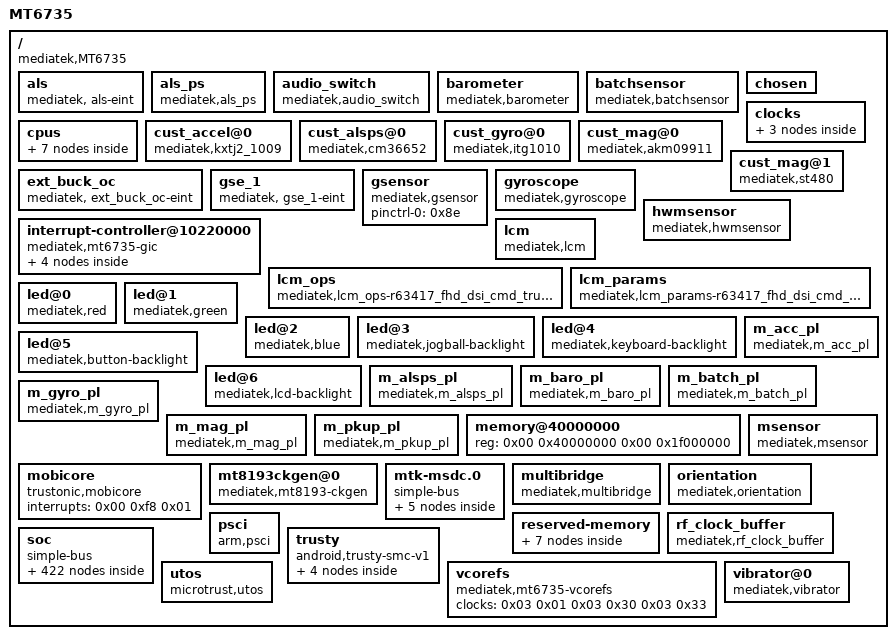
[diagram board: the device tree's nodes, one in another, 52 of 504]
/dts-v1/;

/ {
	#address-cells = <0x02>;
	#size-cells = <0x02>;
	compatible = "mediatek,MT6735";
	interrupt-parent = <0x01>;
	model = "MT6735";

	als {
		compatible = "mediatek, als-eint";
		debounce = <0x03 0x00>;
		interrupt-parent = <0x0c>;
		interrupts = <0x03 0x02>;
		status = "okay";
	};

	als_ps {
		compatible = "mediatek,als_ps";
		pinctrl-0 = <0x8f>;
		pinctrl-1 = <0x90>;
		pinctrl-names = "pin_default\0pin_cfg";
		status = "okay";
	};

	audio_switch {
		compatible = "mediatek,audio_switch";
	};

	barometer {
		compatible = "mediatek,barometer";
	};

	batchsensor {
		compatible = "mediatek,batchsensor";
	};

	chosen {
		bootargs = "console=tty0 console=ttyMT0,921600n1 root=/dev/ram initrd=0x44000000,0x300000 loglevel=8 androidboot.hardware=mt6735";
	};

	clocks {

		clk26m {
			#clock-cells = <0x00>;
			clock-frequency = <0x18cba80>;
			compatible = "fixed-clock";
			linux,phandle = <0x3d>;
			phandle = <0x3d>;
		};

		clk32k {
			#clock-cells = <0x00>;
			clock-frequency = <0x7d00>;
			compatible = "fixed-clock";
		};

		clk_null {
			#clock-cells = <0x00>;
			clock-frequency = <0x00>;
			compatible = "fixed-clock";
		};
	};

	cpus {
		#address-cells = <0x01>;
		#size-cells = <0x00>;

		cpu@000 {
			clock-frequency = "M|m";
			compatible = "arm,cortex-a53";
			cpu-idle-states = <0x0d 0x0d 0x0e 0x0e>;
			cpu-release-addr = <0x00 0x40000200>;
			device_type = "cpu";
			enable-method = "mt-boot";
			linux,phandle = <0x0f>;
			phandle = <0x0f>;
			reg = <0x00>;
		};

		cpu@001 {
			clock-frequency = "M|m";
			compatible = "arm,cortex-a53";
			cpu-idle-states = <0x0d 0x0d 0x0e 0x0e>;
			cpu-release-addr = <0x00 0x40000200>;
			device_type = "cpu";
			enable-method = "mt-boot";
			linux,phandle = <0x10>;
			phandle = <0x10>;
			reg = <0x01>;
		};

		cpu@002 {
			clock-frequency = "M|m";
			compatible = "arm,cortex-a53";
			cpu-idle-states = <0x0d 0x0d 0x0e 0x0e>;
			cpu-release-addr = <0x00 0x40000200>;
			device_type = "cpu";
			enable-method = "mt-boot";
			linux,phandle = <0x11>;
			phandle = <0x11>;
			reg = <0x02>;
		};

		cpu@003 {
			clock-frequency = "M|m";
			compatible = "arm,cortex-a53";
			cpu-idle-states = <0x0d 0x0d 0x0e 0x0e>;
			cpu-release-addr = <0x00 0x40000200>;
			device_type = "cpu";
			enable-method = "mt-boot";
			linux,phandle = <0x12>;
			phandle = <0x12>;
			reg = <0x03>;
		};

		idle-states {
			entry-method = "arm,psci";

			cluster-sleep-0 {
				arm,psci-suspend-param = <0x1010000>;
				compatible = "arm,idle-state";
				entry-latency-us = <0x320>;
				exit-latency-us = <0x3e8>;
				linux,phandle = <0x0d>;
				min-residency-us = <0x7d0>;
				phandle = <0x0d>;
			};

			cpu-sleep-0-0 {
				arm,psci-suspend-param = <0x10000>;
				compatible = "arm,idle-state";
				entry-latency-us = <0x258>;
				exit-latency-us = <0x258>;
				linux,phandle = <0x0e>;
				min-residency-us = <0x4b0>;
				phandle = <0x0e>;
			};
		};
	};

	cust_accel@0 {
		compatible = "mediatek,kxtj2_1009";
		direction = <0x04>;
		firlen = <0x00>;
		i2c_addr = <0x4c 0x00 0x00 0x00>;
		i2c_num = <0x02>;
		is_batch_supported = <0x00>;
		power_id = <0xffff>;
		power_vol = <0x00>;
	};

	cust_alsps@0 {
		als_level = <0x00 0x148 0x35d 0x561 0xc35 0x1e29 0x1e57 0x314d 0x5a16 0x6f0e 0x81fa 0xb80c 0xe15e 0xe15e 0xffff>;
		als_value = <0x00 0x85 0x130 0x1f6 0x3ec 0x7d5 0xbf2 0x138d 0x1f48 0x271a 0x2ee0 0x3e80 0x4e20 0x4e20 0x4e20 0x4e20>;
		compatible = "mediatek,cm36652";
		i2c_addr = <0x60 0x00 0x00 0x00>;
		i2c_num = <0x02>;
		is_batch_supported_als = <0x00>;
		is_batch_supported_ps = <0x00>;
		polling_mode_als = <0x01>;
		polling_mode_ps = <0x00>;
		power_id = <0xffff>;
		power_vol = <0x00>;
		ps_threshold_high = <0x1a>;
		ps_threshold_low = <0x15>;
	};

	cust_gyro@0 {
		compatible = "mediatek,itg1010";
		direction = <0x03>;
		firlen = <0x00>;
		i2c_addr = <0x68 0x00 0x00 0x00>;
		i2c_num = <0x02>;
		is_batch_supported = <0x00>;
		power_id = <0xffff>;
		power_vol = <0x00>;
	};

	cust_mag@0 {
		compatible = "mediatek,akm09911";
		direction = <0x03>;
		i2c_addr = <0x0c 0x00 0x00 0x00>;
		i2c_num = <0x02>;
		is_batch_supported = <0x00>;
		power_id = <0xffff>;
		power_vol = <0x00>;
	};

	cust_mag@1 {
		compatible = "mediatek,st480";
		direction = <0x05>;
		i2c_addr = <0x0c 0x00 0x00 0x00>;
		i2c_num = <0x02>;
		is_batch_supported = <0x00>;
		power_id = <0xffff>;
		power_vol = <0x00>;
	};

	ext_buck_oc {
		compatible = "mediatek, ext_buck_oc-eint";
		debounce = <0x4e 0x00>;
		interrupt-parent = <0x0c>;
		interrupts = <0x4e 0x04>;
		status = "okay";
	};

	gse_1 {
		compatible = "mediatek, gse_1-eint";
		debounce = <0x04 0x00>;
		interrupt-parent = <0x0c>;
		interrupts = <0x04 0x01>;
		status = "okay";
	};

	gsensor {
		compatible = "mediatek,gsensor";
		pinctrl-0 = <0x8e>;
		pinctrl-names = "pin_cfg";
		status = "okay";
	};

	gyroscope {
		compatible = "mediatek,gyroscope";
		debounce = <0x43 0x00>;
		interrupt-parent = <0x0c>;
		interrupts = <0x43 0x08>;
		pinctrl-0 = <0x91>;
		pinctrl-1 = <0x92>;
		pinctrl-names = "pin_default\0pin_cfg";
		status = "okay";
	};

	hwmsensor {
		compatible = "mediatek,hwmsensor";
	};

	interrupt-controller@10220000 {
		#address-cells = <0x00>;
		#interrupt-cells = <0x03>;
		compatible = "mediatek,mt6735-gic";
		interrupt-controller;
		linux,phandle = <0x01>;
		mediatek,wdt_irq = <0xa0>;
		phandle = <0x01>;
		reg = <0x00 0x10221000 0x00 0x1000 0x00 0x10222000 0x00 0x1000 0x00 0x10200620 0x00 0x1000>;

		gic-cpuif@0 {
			compatible = "arm,gic-cpuif";
			cpu = <0x0f>;
			cpuif-id = <0x00>;
		};

		gic-cpuif@1 {
			compatible = "arm,gic-cpuif";
			cpu = <0x10>;
			cpuif-id = <0x01>;
		};

		gic-cpuif@2 {
			compatible = "arm,gic-cpuif";
			cpu = <0x11>;
			cpuif-id = <0x02>;
		};

		gic-cpuif@3 {
			compatible = "arm,gic-cpuif";
			cpu = <0x12>;
			cpuif-id = <0x03>;
		};
	};

	lcm {
		compatible = "mediatek,lcm";
	};

	lcm_ops {
		backlight = <0x04 0x05 0x03 0x51 0x01 0xff>;
		compare_id = <0x03 0x01 0x01 0x01 0x03 0x02 0x01 0x01 0x03 0x01 0x01 0x00 0x03 0x02 0x01 0x0a 0x03 0x01 0x01 0x01 0x03 0x02 0x01 0x0a 0x04 0x04 0x05 0x01 0x00 0x37 0x02 0x00 0x04 0x07 0x03 0xf4 0x01 0x95>;
		compatible = "mediatek,lcm_ops-r63417_fhd_dsi_cmd_truly_nt50358_drv";
		init = <0x01 0x01 0x01 0x00 0x01 0x02 0x01 0x01 0x01 0x03 0x01 0x01 0x03 0x02 0x01 0x0a 0x02 0x01 0x02 0x00 0x0a 0x02 0x01 0x02 0x01 0x0a 0x03 0x01 0x01 0x01 0x03 0x02 0x01 0x01 0x03 0x01 0x01 0x00 0x03 0x02 0x01 0x0a 0x03 0x01 0x01 0x01 0x03 0x02 0x01 0x0a 0x04 0x05 0x03 0xb0 0x01 0x00 0x04 0x05 0x03 0xd6 0x01 0x01 0x04 0x05 0x03 0x51 0x01 0xff 0x04 0x05 0x03 0x53 0x01 0x0c 0x04 0x05 0x2a 0xc6 0x28 0x77 0x01 0x71 0x07 0x65 0x00 0x00 0x00 0x00 0x00 0x00 0x00 0x00 0x00 0x00 0x00 0x00 0x09 0x19 0x09 0x77 0x01 0x71 0x07 0x65 0x00 0x00 0x00 0x00 0x00 0x00 0x00 0x00 0x00 0x00 0x00 0x00 0x09 0x19 0x09 0x04 0x05 0x20 0xc7 0x1e 0x01 0x0c 0x14 0x1e 0x2d 0x3c 0x48 0x58 0x3d 0x44 0x4f 0x5c 0x65 0x6d 0x75 0x01 0x0c 0x14 0x1d 0x2c 0x39 0x44 0x54 0x39 0x41 0x4d 0x5a 0x63 0x6b 0x74 0x04 0x05 0x15 0xc8 0x13 0x01 0x00 0xff 0xff 0x00 0xfc 0x00 0x00 0xff 0xff 0x00 0xfc 0x00 0x00 0xff 0xff 0x00 0xfc 0x00 0x04 0x05 0x03 0x35 0x01 0x00 0x04 0x05 0x04 0xb6 0x02 0x3a 0xd3 0x04 0x05 0x02 0x29 0x00 0x04 0x05 0x02 0x11 0x00 0x03 0x02 0x01 0x78>;
		suspend = <0x04 0x05 0x02 0x28 0x00 0x03 0x02 0x01 0x14 0x04 0x05 0x02 0x10 0x00 0x04 0x05 0x03 0xb0 0x01 0x00 0x04 0x05 0x03 0xb1 0x01 0x01 0x03 0x02 0x01 0x50 0x03 0x02 0x01 0x0a 0x01 0x01 0x01 0x00 0x01 0x02 0x01 0x01 0x01 0x03 0x01 0x00>;
	};

	lcm_params {
		compatible = "mediatek,lcm_params-r63417_fhd_dsi_cmd_truly_nt50358_drv";
		lcm_params-dbi-clock_freq;
		lcm_params-dbi-cpu_write_bits;
		lcm_params-dbi-ctrl_io_driving_current;
		lcm_params-dbi-data_format;
		lcm_params-dbi-data_width;
		lcm_params-dbi-io_driving_current;
		lcm_params-dbi-msb_io_driving_current;
		lcm_params-dbi-parallel-params0;
		lcm_params-dbi-parallel-params1;
		lcm_params-dbi-port;
		lcm_params-dbi-serial-params0;
		lcm_params-dbi-serial-params1;
		lcm_params-dbi-serial-params2;
		lcm_params-dbi-te_edge_polarity;
		lcm_params-dbi-te_hs_delay_cnt;
		lcm_params-dbi-te_mode;
		lcm_params-dbi-te_vs_width_cnt;
		lcm_params-dbi-te_vs_width_cnt_div;
		lcm_params-dpi-PLL_CLOCK;
		lcm_params-dpi-bg_height;
		lcm_params-dpi-bg_width;
		lcm_params-dpi-bit_swap;
		lcm_params-dpi-clk_pol;
		lcm_params-dpi-de_pol;
		lcm_params-dpi-dpi_clk_div;
		lcm_params-dpi-dpi_clk_duty;
		lcm_params-dpi-dpi_clock;
		lcm_params-dpi-embsync;
		lcm_params-dpi-format;
		lcm_params-dpi-height;
		lcm_params-dpi-hsync_back_porch;
		lcm_params-dpi-hsync_front_porch;
		lcm_params-dpi-hsync_pol;
		lcm_params-dpi-hsync_pulse_width;
		lcm_params-dpi-i2x_edge;
		lcm_params-dpi-i2x_en;
		lcm_params-dpi-intermediat_buffer_num;
		lcm_params-dpi-io_driving_current;
		lcm_params-dpi-is_serial_output;
		lcm_params-dpi-lsb_io_driving_current;
		lcm_params-dpi-lvds_tx_en;
		lcm_params-dpi-mipi_pll_clk_div1;
		lcm_params-dpi-mipi_pll_clk_div2;
		lcm_params-dpi-mipi_pll_clk_fbk_div;
		lcm_params-dpi-mipi_pll_clk_ref;
		lcm_params-dpi-rgb_order;
		lcm_params-dpi-ssc_disable;
		lcm_params-dpi-ssc_range;
		lcm_params-dpi-vsync_back_porch;
		lcm_params-dpi-vsync_front_porch;
		lcm_params-dpi-vsync_pol;
		lcm_params-dpi-vsync_pulse_width;
		lcm_params-dpi-width;
		lcm_params-dsi-CLK_HS_EXIT;
		lcm_params-dsi-CLK_HS_POST;
		lcm_params-dsi-CLK_HS_PRPR;
		lcm_params-dsi-CLK_TRAIL;
		lcm_params-dsi-CLK_ZERO;
		lcm_params-dsi-CONT_DET;
		lcm_params-dsi-DA_HS_EXIT;
		lcm_params-dsi-DSI_RMEM_CONTI;
		lcm_params-dsi-DSI_WMEM_CONTI;
		lcm_params-dsi-HS_PRPR;
		lcm_params-dsi-HS_TRAIL;
		lcm_params-dsi-LPX;
		lcm_params-dsi-LPX_WAIT;
		lcm_params-dsi-TA_GET;
		lcm_params-dsi-TA_GO;
		lcm_params-dsi-TA_SACK;
		lcm_params-dsi-TA_SURE;
		lcm_params-dsi-VC_NUM;
		lcm_params-dsi-ZERO;
		lcm_params-dsi-clk_lp_per_line_enable = <0x00>;
		lcm_params-dsi-compatibility_for_nvk;
		lcm_params-dsi-cont_clock;
		lcm_params-dsi-customization_esd_check_enable = <0x00>;
		lcm_params-dsi-data_format = <0x02 0x00 0x00 0x02>;
		lcm_params-dsi-dsi_clock;
		lcm_params-dsi-dual_dsi_type;
		lcm_params-dsi-edp_panel;
		lcm_params-dsi-esd_check_enable = <0x01>;
		lcm_params-dsi-fbk_div;
		lcm_params-dsi-fbk_sel;
		lcm_params-dsi-horizontal_active_pixel = <0x438>;
		lcm_params-dsi-horizontal_backporch = <0x3c>;
		lcm_params-dsi-horizontal_backporch_word_count;
		lcm_params-dsi-horizontal_backportch_byte;
		lcm_params-dsi-horizontal_blanking_pixel;
		lcm_params-dsi-horizontal_bllp;
		lcm_params-dsi-horizontal_frontporch = <0x64>;
		lcm_params-dsi-horizontal_frontporch_byte;
		lcm_params-dsi-horizontal_frontporch_word_count;
		lcm_params-dsi-horizontal_sync_active = <0x0a>;
		lcm_params-dsi-horizontal_sync_active_byte;
		lcm_params-dsi-horizontal_sync_active_word_count;
		lcm_params-dsi-intermediat_buffer_num;
		lcm_params-dsi-lane_num = <0x04>;
		lcm_params-dsi-lane_swap0;
		lcm_params-dsi-lane_swap1;
		lcm_params-dsi-lane_swap_en;
		lcm_params-dsi-lcm_esd_check_table0 = <0x0a 0x01 0x1c 0x00>;
		lcm_params-dsi-lcm_esd_check_table1;
		lcm_params-dsi-lcm_esd_check_table2;
		lcm_params-dsi-lcm_ext_te_enable;
		lcm_params-dsi-lcm_ext_te_monitor;
		lcm_params-dsi-lcm_int_te_monitor;
		lcm_params-dsi-lcm_int_te_period;
		lcm_params-dsi-line_byte;
		lcm_params-dsi-mode = <0x00>;
		lcm_params-dsi-noncont_clock;
		lcm_params-dsi-noncont_clock_period;
		lcm_params-dsi-packet_size = <0x100>;
		lcm_params-dsi-pll_clock = <0x1c2>;
		lcm_params-dsi-pll_div1;
		lcm_params-dsi-pll_div2;
		lcm_params-dsi-pll_select;
		lcm_params-dsi-ps = <0x02>;
		lcm_params-dsi-rg_bic;
		lcm_params-dsi-rg_bir;
		lcm_params-dsi-rg_bp;
		lcm_params-dsi-rgb_byte;
		lcm_params-dsi-ssc_disable;
		lcm_params-dsi-ssc_range;
		lcm_params-dsi-switch_mode = <0x02>;
		lcm_params-dsi-switch_mode_enable = <0x00>;
		lcm_params-dsi-ufoe_enable;
		lcm_params-dsi-ufoe_params;
		lcm_params-dsi-vertical_active_line = <0x780>;
		lcm_params-dsi-vertical_backporch = <0x08>;
		lcm_params-dsi-vertical_frontporch = <0x0a>;
		lcm_params-dsi-vertical_frontporch_for_low_power;
		lcm_params-dsi-vertical_sync_active = <0x02>;
		lcm_params-dsi-vertical_vfp_lp;
		lcm_params-dsi-word_count;
		lcm_params-io_select_mode;
		lcm_params-od_table;
		lcm_params-od_table_size;
		lcm_params-physical_height;
		lcm_params-physical_width;
		lcm_params-resolution = <0x438 0x780>;
		lcm_params-types = <0x02 0x00 0x00 0x00>;
	};

	led@0 {
		compatible = "mediatek,red";
		data = <0x01>;
		led_mode = <0x00>;
		pwm_config = <0x00 0x00 0x00 0x00 0x00>;
	};

	led@1 {
		compatible = "mediatek,green";
		data = <0x01>;
		led_mode = <0x00>;
		pwm_config = <0x00 0x00 0x00 0x00 0x00>;
	};

	led@2 {
		compatible = "mediatek,blue";
		data = <0x01>;
		led_mode = <0x00>;
		pwm_config = <0x00 0x00 0x00 0x00 0x00>;
	};

	led@3 {
		compatible = "mediatek,jogball-backlight";
		data = <0x01>;
		led_mode = <0x00>;
		pwm_config = <0x00 0x00 0x00 0x00 0x00>;
	};

	led@4 {
		compatible = "mediatek,keyboard-backlight";
		data = <0x01>;
		led_mode = <0x00>;
		pwm_config = <0x00 0x00 0x00 0x00 0x00>;
	};

	led@5 {
		compatible = "mediatek,button-backlight";
		data = <0x01>;
		led_mode = <0x00>;
		pwm_config = <0x00 0x00 0x00 0x00 0x00>;
	};

	led@6 {
		compatible = "mediatek,lcd-backlight";
		data = <0x01>;
		led_mode = <0x05>;
		pwm_config = <0x00 0x00 0x00 0x00 0x00>;
	};

	m_acc_pl {
		compatible = "mediatek,m_acc_pl";
	};

	m_alsps_pl {
		compatible = "mediatek,m_alsps_pl";
	};

	m_baro_pl {
		compatible = "mediatek,m_baro_pl";
	};

	m_batch_pl {
		compatible = "mediatek,m_batch_pl";
	};

	m_gyro_pl {
		compatible = "mediatek,m_gyro_pl";
	};

	m_mag_pl {
		compatible = "mediatek,m_mag_pl";
	};

	m_pkup_pl {
		compatible = "mediatek,m_pkup_pl";
	};

	memory@40000000 {
		device_type = "memory";
		reg = <0x00 0x40000000 0x00 0x1f000000>;
	};

	mobicore {
		compatible = "trustonic,mobicore";
		interrupts = <0x00 0xf8 0x01>;
	};

	msensor {
		compatible = "mediatek,msensor";
	};

	mt8193ckgen@0 {
		bus_switch_pin = <0x0b 0x00 0x00>;
		compatible = "mediatek,mt8193-ckgen";
		pinctrl-0 = <0x93>;
		pinctrl-1 = <0x94>;
		pinctrl-2 = <0x95>;
		pinctrl-names = "default\0bus_switch_gpio\0bus_switch_dpi";
		status = "okay";
	};

	mtk-msdc.0 {
		#address-cells = <0x01>;
		#size-cells = <0x01>;
		compatible = "simple-bus";
		ranges = <0x00 0x00 0x00 0xffffffff>;

		default {
			compatible = "mediatek, msdc1_ins-eint";
			debounce = <0x05 0x3e8>;
			interrupt-parent = <0x0c>;
			interrupts = <0x05 0x08>;
			status = "okay";
		};

		msdc0@11230000 {
			bootable;
			bus-width = <0x08>;
			cap-mmc-highspeed;
			clk_src = [02];
			clock-names = "MSDC0-CLOCK\0MSDC0_PLL_SEL\0MSDC0_PLL_800M\0MSDC0_PLL_400M\0MSDC0_PLL_200M";
			clocks = <0x02 0x0e 0x03 0x0d 0x03 0x29 0x03 0x2b 0x03 0x2c>;
			compatible = "mediatek,mt6735-mmc";
			host_function = [00];
			interrupts = <0x00 0x4f 0x08>;
			max-frequency = <0xbebc200>;
			mmc-ddr-1_8v;
			mmc-hs200-1_8v;
			mmc-hs400-1_8v;
			msdc-sys-suspend;
			non-removable;
			pinctl = <0x04>;
			reg = <0x11230000 0x10000 0x10000e84 0x02>;
			register_setting = <0x05>;
			status = "okay";
		};

		msdc1@11240000 {
			bus-width = <0x04>;
			cap-sd-highspeed;
			cd-gpios = <0x0b 0x05 0x00>;
			cd_level = [00];
			clk_src = [02];
			clock-names = "MSDC1-CLOCK";
			clocks = <0x02 0x0f>;
			compatible = "mediatek,mt6735-mmc";
			host_function = [01];
			interrupts = <0x00 0x50 0x08>;
			max-frequency = <0xbebc200>;
			msdc-sys-suspend;
			pinctl = <0x06>;
			pinctl_ddr50 = <0x09>;
			pinctl_sdr104 = <0x07>;
			pinctl_sdr50 = <0x08>;
			reg = <0x11240000 0x10000 0x10000e84 0x02>;
			register_setting = <0x0a>;
			sd-uhs-ddr50;
			sd-uhs-sdr104;
			sd-uhs-sdr12;
			sd-uhs-sdr25;
			sd-uhs-sdr50;
			status = "okay";
		};

		msdc2@11250000 {
			clock-names = "MSDC2-CLOCK";
			clocks = <0x02 0x10>;
			compatible = "mediatek,mt6735-mmc";
			interrupts = <0x00 0x51 0x08>;
			reg = <0x11250000 0x10000 0x10000e84 0x02>;
			status = "disabled";
		};

		msdc3@11260000 {
			bus-width = <0x04>;
			cap-sd-highspeed;
			clk_src = [02];
			clock-names = "MSDC3-CLOCK";
			clocks = <0x02 0x11>;
			compatible = "mediatek,mt6735-mmc";
			host_function = [02];
			interrupts = <0x00 0x52 0x08>;
			max-frequency = <0x2faf080>;
			non-removable;
			reg = <0x11260000 0x10000 0x10000e84 0x02>;
			sd-uhs-sdr12;
			sd-uhs-sdr25;
			sd-uhs-sdr50;
			status = "okay";
		};
	};

	multibridge {
		compatible = "mediatek,multibridge";
	};

	orientation {
		compatible = "mediatek,orientation";
	};

	psci {
		affinity_info = <0x84000004>;
		compatible = "arm,psci";
		cpu_off = <0x84000002>;
		cpu_on = <0x84000003>;
		cpu_suspend = <0x84000001>;
		method = "smc";
	};

	reserved-memory {
		#address-cells = <0x02>;
		#size-cells = <0x02>;
		ranges;

		atf-reserved-memory@43000000 {
			compatible = "mediatek,mt6735-atf-reserved-memory\0mediatek,mt6735m-atf-reserved-memory\0mediatek,mt6753-atf-reserved-memory";
			no-map;
			reg = <0x00 0x43000000 0x00 0x30000>;
		};

		consys-reserve-memory {
			alignment = <0x00 0x200000>;
			compatible = "mediatek,consys-reserve-memory";
			no-map;
			size = <0x00 0x100000>;
		};

		minirdump-reserved-memory@43ff0000 {
			compatible = "mediatek,minirdump";
			reg = <0x00 0x43ff0000 0x00 0x10000>;
		};

		pstore-reserved-memory@43f10000 {
			compatible = "mediatek,pstore";
			reg = <0x00 0x43f10000 0x00 0xe0000>;
		};

		ram_console-reserved-memory@43f00000 {
			compatible = "mediatek,ram_console";
			reg = <0x00 0x43f00000 0x00 0x10000>;
		};

		reserve-memory-ccci_md1 {
			alignment = <0x00 0x2000000>;
			alloc-ranges = <0x00 0x40000000 0x00 0xc0000000>;
			compatible = "mediatek,reserve-memory-ccci_md1";
			no-map;
			size = <0x00 0x3810000>;
		};

		reserve-memory-ccci_md3 {
			alignment = <0x00 0x2000000>;
			alloc-ranges = <0x00 0x40000000 0x00 0xc0000000>;
			compatible = "mediatek,reserve-memory-ccci_md3";
			no-map;
			size = <0x00 0xb00000>;
		};
	};

	rf_clock_buffer {
		compatible = "mediatek,rf_clock_buffer";
		mediatek,clkbuf-config = <0x02 0x02 0x02 0x02>;
		mediatek,clkbuf-quantity = <0x04>;
		status = "okay";
	};

	soc {
		#address-cells = <0x01>;
		#size-cells = <0x01>;
		compatible = "simple-bus";
		ranges = <0x00 0x00 0x00 0xffffffff>;

		BAT_NOTIFY {
			compatible = "mediatek,bat_notify";
		};

		accdet {
			accdet-mic-mode = <0x01>;
			accdet-mic-vol = <0x07>;
			accdet-plugout-debounce = <0x14>;
			compatible = "mediatek,mt6735-accdet";
			debounce = <0x06 0x3e800>;
			headset-four-key-threshold = <0x00 0x3a 0x79 0xc0 0x1c2>;
			headset-mode-setting = <0x500 0x200 0x01 0x1f0 0x800 0x800 0x20>;
			headset-three-key-threshold = <0x00 0x50 0xdc 0x1f4>;
			interrupt-parent = <0x0c>;
			interrupts = <0x06 0x08>;
			pinctrl-0 = <0x70>;
			pinctrl-1 = <0x76>;
			pinctrl-names = "default\0state_eint_as_int";
			status = "okay";
		};

		adc_hw@11001000 {
			clock-names = "auxadc-main";
			clocks = <0x02 0x1c>;
			compatible = "mediatek,mt6735-auxadc";
			interrupts = <0x00 0x4c 0x02>;
			reg = <0x11001000 0x1000>;

			adc_channel@ {
				compatible = "mediatek,adc_channel";
				mediatek,adc_fdd_rf_params_dynamic_custom_ch = <0x0c>;
				mediatek,temperature0 = <0x00>;
				mediatek,temperature1 = <0x01>;
				status = "okay";
			};
		};

		apmixed@10209000 {
			compatible = "mediatek,apmixed";
			reg = <0x10209000 0x1000>;
		};

		apmixedsys@10209000 {
			#clock-cells = <0x01>;
			compatible = "mediatek,mt6735-apmixedsys";
			linux,phandle = <0x3c>;
			phandle = <0x3c>;
			reg = <0x10209000 0x1000>;
		};

		apuart0@11002000 {
			cell-index = <0x00>;
			clock-div = <0x01>;
			clock-frequency = <0x18cba80>;
			clock-names = "uart0-main\0uart-apdma";
			clocks = <0x02 0x12 0x02 0x0d>;
			compatible = "mediatek,mt6735-uart";
			interrupts = <0x00 0x5b 0x08 0x00 0x67 0x08 0x00 0x68 0x08>;
			pinctrl-0 = <0x21>;
			pinctrl-1 = <0x22>;
			pinctrl-2 = <0x23>;
			pinctrl-3 = <0x24>;
			pinctrl-4 = <0x25>;
			pinctrl-names = "uart0_gpio_default\0uart0_rx_set\0uart0_rx_clear\0uart0_tx_set\0uart0_tx_clear";
			reg = <0x11002000 0x1000 0x11000380 0x1000 0x11000400 0x80>;
			status = "okay";
		};

		apuart1@11003000 {
			cell-index = <0x01>;
			clock-div = <0x01>;
			clock-frequency = <0x18cba80>;
			clock-names = "uart1-main";
			clocks = <0x02 0x13>;
			compatible = "mediatek,mt6735-uart";
			interrupts = <0x00 0x5c 0x08 0x00 0x69 0x08 0x00 0x6a 0x08>;
			pinctrl-0 = <0x26>;
			pinctrl-1 = <0x27>;
			pinctrl-2 = <0x28>;
			pinctrl-3 = <0x29>;
			pinctrl-4 = <0x2a>;
			pinctrl-names = "uart1_gpio_default\0uart1_rx_set\0uart1_rx_clear\0uart1_tx_set\0uart1_tx_clear";
			reg = <0x11003000 0x1000 0x11000480 0x80 0x11000500 0x80>;
			status = "okay";
		};

		apuart2@11004000 {
			cell-index = <0x02>;
			clock-div = <0x01>;
			clock-frequency = <0x18cba80>;
			clock-names = "uart2-main";
			clocks = <0x02 0x14>;
			compatible = "mediatek,mt6735-uart";
			interrupts = <0x00 0x5d 0x08 0x00 0x6b 0x08 0x00 0x6c 0x08>;
			pinctrl-0 = <0x2b>;
			pinctrl-1 = <0x2c>;
			pinctrl-2 = <0x2d>;
			pinctrl-3 = <0x2e>;
			pinctrl-4 = <0x2f>;
			pinctrl-names = "uart2_gpio_default\0uart2_rx_set\0uart2_rx_clear\0uart2_tx_set\0uart2_tx_clear";
			reg = <0x11004000 0x1000 0x11000580 0x80 0x11000600 0x80>;
			status = "okay";
		};

		apuart3@11005000 {
			cell-index = <0x03>;
			clock-div = <0x01>;
			clock-frequency = <0x18cba80>;
			clock-names = "uart3-main";
			clocks = <0x02 0x15>;
			compatible = "mediatek,mt6735-uart";
			interrupts = <0x00 0x5e 0x08 0x00 0x6d 0x08 0x00 0x6e 0x08>;
			pinctrl-0 = <0x30>;
			pinctrl-1 = <0x31>;
			pinctrl-2 = <0x32>;
			pinctrl-3 = <0x33>;
			pinctrl-4 = <0x34>;
			pinctrl-names = "uart3_gpio_default\0uart3_rx_set\0uart3_rx_clear\0uart3_tx_set\0uart3_tx_clear";
			reg = <0x11005000 0x1000 0x11000680 0x80 0x11000700 0x80>;
			status = "okay";
		};

		apuart4@1100D000 {
			cell-index = <0x04>;
			clock-div = <0x01>;
			clock-frequency = <0x18cba80>;
			clock-names = "uart4-main";
			clocks = <0x02 0x16>;
			compatible = "mediatek,mt6735-uart";
			interrupts = <0x00 0x5f 0x08 0x00 0x6f 0x08 0x00 0x70 0x08>;
			reg = <0x1100d000 0x1000 0x11000780 0x80 0x11000800 0x80>;
		};

		apxgpt@10004000 {
			clock-frequency = <0xc65d40>;
			compatible = "mediatek,mt6735-apxgpt";
			interrupts = <0x00 0x98 0x08>;
			reg = <0x10004000 0x1000>;
		};

		audio@11220000 {
			compatible = "mediatek,audio";
			interrupts = <0x00 0x90 0x08>;
			reg = <0x11220000 0x10000>;
		};

		audiosys@11220000 {
			#clock-cells = <0x01>;
			compatible = "mediatek,mt6735-audiosys";
			linux,phandle = <0x3b>;
			phandle = <0x3b>;
			reg = <0x11220000 0x10000>;
		};

		bat_comm {
			compatible = "mediatek,battery";
		};

		bat_meter {
			compatible = "mediatek,bat_meter";
		};

		btcvsd@10000000 {
			compatible = "mediatek,audio_bt_cvsd";
			interrupts = <0x00 0xe4 0x08>;
			offset = <0x700 0x800 0xfd0 0xfd4 0xfd8>;
			reg = <0x10000000 0x1000 0x18000000 0x10000 0x18080000 0x8000>;
		};

		btif@1100c000 {
			clock-names = "btifc\0apdmac";
			clocks = <0x02 0x17 0x02 0x0d>;
			compatible = "mediatek,btif";
			interrupts = <0x00 0x5a 0x08>;
			reg = <0x1100c000 0x1000>;
		};

		btif_rx@11000900 {
			compatible = "mediatek,btif_rx";
			interrupts = <0x00 0x72 0x08>;
			reg = <0x11000900 0x80>;
		};

		btif_tx@11000880 {
			compatible = "mediatek,btif_tx";
			interrupts = <0x00 0x71 0x08>;
			reg = <0x11000880 0x80>;
		};

		bus_dbg@10208000 {
			compatible = "mediatek,bus_dbg-v1";
			interrupts = <0x00 0x89 0x08>;
			reg = <0x10208000 0x1000>;
		};

		c2k_sdio@0 {
			compatible = "mediatek,mt6735-c2k_sdio";
			interrupts = <0x00 0xe6 0x08>;
		};

		ccci_off {
			clock-names = "scp-sys-md1-main";
			clocks = <0x13 0x01>;
			compatible = "mediatek,ccci_off";
		};

		chipid@08000000 {
			compatible = "mediatek,chipid";
			reg = <0x8000000 0x04 0x8000004 0x04 0x8000008 0x04 0x800000c 0x04>;
		};

		cksys@10210000 {
			compatible = "mediatek,cksys";
			reg = <0x10210000 0x1000>;
		};

		consys@18070000 {
			clock-names = "conn\0bus";
			clocks = <0x13 0x03 0x19 0x0b>;
			compatible = "mediatek,mt6735-consys";
			interrupts = <0x00 0xe3 0x08 0x00 0xe1 0x08>;
			pinctrl-0 = <0x6b>;
			pinctrl-1 = <0x6c>;
			pinctrl-2 = <0x6d>;
			pinctrl-3 = <0x6e>;
			pinctrl-names = "default\0gps_lna_state_init\0gps_lna_state_oh\0gps_lna_state_ol";
			reg = <0x18070000 0x200 0x10212000 0x100 0x10000000 0x2000 0x10006000 0x1000>;
			status = "okay";
			vcn18-supply = <0x67>;
			vcn28-supply = <0x68>;
			vcn33_bt-supply = <0x69>;
			vcn33_wifi-supply = <0x6a>;
		};

		cpu_dbgapb@0x10810000 {
			compatible = "mediatek,mt6735-dbg_debug";
			num = <0x04>;
			reg = <0x10810000 0x1000 0x10910000 0x1000 0x10a10000 0x1000 0x10b10000 0x1000>;
		};

		cpuxgpt@10200000 {
			compatible = "mediatek,mt6735-cpuxgpt";
			interrupts = <0x00 0x40 0x04 0x00 0x41 0x04 0x00 0x42 0x04 0x00 0x43 0x04 0x00 0x44 0x04 0x00 0x45 0x04 0x00 0x46 0x04 0x00 0x47 0x04>;
			reg = <0x10200000 0x1000>;
		};

		cqdma@10217c00 {
			compatible = "mediatek,cqdma";
			interrupts = <0x00 0x97 0x08>;
			nr_channel = <0x01>;
			reg = <0x10217c00 0xc00>;
		};

		dbgapb_base@1011a000 {
			compatible = "mediatek,dbgapb_base";
			reg = <0x1011a000 0x100>;
		};

		ddrphy@10213000 {
			compatible = "mediatek,mt6735-ddrphy";
			reg = <0x10213000 0x1000>;
		};

		devapc@10207000 {
			clock-names = "devapc-main";
			clocks = <0x19 0x05>;
			compatible = "mediatek,devapc";
			interrupts = <0x00 0x86 0x08>;
			reg = <0x10207000 0x1000>;
		};

		devapc_ao@10007000 {
			compatible = "mediatek,devapc_ao";
			reg = <0x10007000 0x1000>;
		};

		dispsys@14007000 {
			clock-names = "DISP0_SMI_COMMON\0DISP0_SMI_LARB0\0DISP0_DISP_OVL0\0DISP0_DISP_RDMA0\0DISP0_DISP_RDMA1\0DISP0_DISP_WDMA0\0DISP0_DISP_COLOR\0DISP0_DISP_CCORR\0DISP0_DISP_AAL\0DISP0_DISP_GAMMA\0DISP0_DISP_DITHER\0DISP1_DSI_ENGINE\0DISP1_DSI_DIGITAL\0DISP1_DPI_ENGINE\0DISP1_DPI_PIXEL\0DISP_PWM\0MUX_DPI0\0TVDPLL\0TVDPLL_CK\0TVDPLL_D2\0TVDPLL_D4\0DPI_CK\0MUX_DISPPWM\0UNIVPLL2_D4\0SYSPLL4_D2_D8\0AD_SYS_26M_CK\0DISP_MTCMOS_CLK";
			clocks = <0x1a 0x01 0x1a 0x02 0x1a 0x0b 0x1a 0x0c 0x1a 0x0d 0x1a 0x0e 0x1a 0x0f 0x1a 0x10 0x1a 0x11 0x1a 0x12 0x1a 0x13 0x1a 0x14 0x1a 0x15 0x1a 0x16 0x1a 0x17 0x02 0x01 0x03 0x16 0x3c 0x07 0x03 0x3c 0x03 0x3d 0x03 0x3e 0x03 0x4d 0x03 0x1d 0x03 0x45 0x03 0x3a 0x03 0x22 0x13 0x04>;
			compatible = "mediatek,mt6735-dispsys";
			interrupts = <0x00 0xc1 0x08 0x00 0x00 0x08 0x00 0xc2 0x08 0x00 0xc3 0x08 0x00 0xc4 0x08 0x00 0xc5 0x08 0x00 0xc6 0x08 0x00 0xc7 0x08 0x00 0xc8 0x08 0x00 0xc9 0x08 0x00 0x00 0x08 0x00 0x75 0x08 0x00 0x00 0x08 0x00 0xba 0x08 0x00 0xcb 0x08 0x00 0xcc 0x08 0x00 0xcd 0x08 0x00 0xb0 0x08 0x00 0x00 0x08 0x00 0x00 0x08 0x00 0x00 0x08 0x00 0x00 0x08 0x00 0x00 0x08 0x00 0x00 0x08 0x00 0x00 0x08 0x00 0x00 0x08 0x00 0x00 0x08 0x00 0x00 0x08>;
			reg = <0x14007000 0x1000 0x00 0x00 0x14008000 0x1000 0x14009000 0x1000 0x1400a000 0x1000 0x1400b000 0x1000 0x1400c000 0x1000 0x1400d000 0x1000 0x1400e000 0x1000 0x1400f000 0x1000 0x00 0x00 0x1100e000 0x1000 0x00 0x00 0x14014000 0x1000 0x14011000 0x1000 0x14012000 0x1000 0x14000000 0x1000 0x14015000 0x1000 0x14016000 0x1000 0x14017000 0x1000 0x10206000 0x1000 0x10210000 0x1000 0x10211a70 0x0c 0x10211974 0x0c 0x10211b70 0x0c 0x10206044 0x0c 0x10206514 0x0c 0x10206558 0x0c 0x102100a0 0x1000 0x10209270 0x1000 0x10209274 0x1000 0x00 0x00 0x10209000 0x1000>;
		};

		dma@11000000 {
			compatible = "mediatek,ap_dma";
			interrupts = <0x00 0x72 0x08>;
			reg = <0x11000000 0x1000>;
		};

		dpi@14012000 {
			compatible = "mediatek,mt6735-dpi";
			interrupts = <0x00 0xcc 0x08>;
			reg = <0x14012000 0x1000>;
		};

		dramc@10214000 {
			clock-names = "infra-cqdma";
			clocks = <0x19 0x02>;
			compatible = "mediatek,mt6735-dramc";
			reg = <0x10214000 0x1000>;
		};

		dramc_nao@1020e000 {
			compatible = "mediatek,mt6735-dramc_nao";
			reg = <0x1020e000 0x1000>;
		};

		dsi_te {
			compatible = "mediatek, dsi_te_1-eint";
			debounce = <0x93 0x00>;
			interrupt-parent = <0x0c>;
			interrupts = <0x93 0x01>;
			status = "okay";
		};

		efusec@10206000 {
			compatible = "mediatek,efusec";
			reg = <0x10206000 0x1000>;
		};

		eintc@10005000 {
			#interrupt-cells = <0x02>;
			compatible = "mediatek,mt-eic";
			interrupt-controller;
			interrupts = <0x00 0x99 0x04>;
			linux,phandle = <0x0c>;
			mediatek,mapping_table_entry = <0x00>;
			mediatek,max_eint_num = <0xd5>;
			phandle = <0x0c>;
			reg = <0x10005000 0x1000>;

			pmic@206 {
				compatible = "mediatek, pmic-eint";
				debounce = <0xce 0x3e8>;
				interrupt-parent = <0x0c>;
				interrupts = <0xce 0x04>;
			};
		};

		emi@10203000 {
			compatible = "mediatek,emi";
			interrupts = <0x00 0x88 0x04>;
			reg = <0x10203000 0x1000>;
		};

		fdvt@1500b000 {
			clock-names = "FD-SCP_SYS_DIS\0FD-SCP_SYS_ISP\0FD-MM_DISP0_SMI_COMMON\0FD-IMG_IMAGE_FD";
			clocks = <0x13 0x04 0x13 0x06 0x1a 0x01 0x1c 0x08>;
			compatible = "mediatek,fdvt";
			interrupts = <0x00 0xd0 0x08>;
			reg = <0x1500b000 0x1000>;
		};

		fhctl@10209f00 {
			compatible = "mediatek,fhctl";
			reg = <0x10209f00 0x100>;
		};

		g3d_config@13000000 {
			compatible = "mediatek,g3d_config";
			reg = <0x13000000 0x1000>;
		};

		gce@10217000 {
			apxgpt2_count = <0x10004028>;
			audio_base = <0x11220000 0x12 0xffff0000>;
			buf_underrun_event_0 = <0x2d>;
			buf_underrun_event_1 = <0x2e>;
			camsv_1_pass1_done = <0x47>;
			camsv_2_pass1_done = <0x46>;
			clock-names = "GCE";
			clocks = <0x19 0x02>;
			compatible = "mediatek,gce";
			conn_peri_base = <0x18000000 0x07 0xffff0000>;
			disp_aal_frame_done = <0x1e>;
			disp_aal_sof = <0x0c>;
			disp_ccorr_frame_done = <0x1c>;
			disp_ccorr_sof = <0x0a>;
			disp_color_frame_done = <0x1d>;
			disp_color_sof = <0x0b>;
			disp_dither_base = <0x14010000 0x02 0xffff0000>;
			disp_dither_frame_done = <0x20>;
			disp_dither_sof = <0x0e>;
			disp_dpi0_frame_done = <0x22>;
			disp_gamma_frame_done = <0x1f>;
			disp_gamma_sof = <0x0d>;
			disp_mutex_reg = <0x14014000 0x1000>;
			disp_ovl0_frame_done = <0x18>;
			disp_ovl0_sof = <0x06>;
			disp_pwm0_sof = <0x10>;
			disp_rdma0_frame_done = <0x19>;
			disp_rdma0_sof = <0x07>;
			disp_rdma1_frame_done = <0x1a>;
			disp_rdma1_sof = <0x08>;
			disp_wdma0_frame_done = <0x1b>;
			disp_wdma0_sof = <0x09>;
			dsi0_te_event = <0x03>;
			g3d_config_base = <0x13000000 0x00 0xffff0000>;
			gcpu_base = <0x10210000 0x0f 0xffff0000>;
			imgsys_base = <0x15000000 0x04 0xffff0000>;
			infra_na3_base = <0x10030000 0x0b 0xffff0000>;
			infra_na4_base = <0x10040000 0x0c 0xffff0000>;
			interrupts = <0x00 0x97 0x08 0x00 0x94 0x08>;
			isp_frame_done_p1_0 = <0x45>;
			isp_frame_done_p1_1 = <0x44>;
			isp_frame_done_p2_0 = <0x43>;
			isp_frame_done_p2_1 = <0x42>;
			isp_frame_done_p2_2 = <0x41>;
			jpgdec_done = <0x83>;
			jpgenc_done = <0x82>;
			kp_base = <0x10010000 0x09 0xffff0000>;
			mcucfg_base = <0x10200000 0x0e 0xffff0000>;
			mdp_rdma0_frame_done = <0x11>;
			mdp_rdma0_sof = <0x00>;
			mdp_rsz0_frame_done = <0x12>;
			mdp_rsz0_sof = <0x01>;
			mdp_rsz1_frame_done = <0x13>;
			mdp_rsz1_sof = <0x02>;
			mdp_tdshp_frame_done = <0x14>;
			mdp_tdshp_sof = <0x2f>;
			mdp_wdma_frame_done = <0x15>;
			mdp_wdma_sof = <0x04>;
			mdp_wrot_read_frame_done = <0x17>;
			mdp_wrot_sof = <0x05>;
			mdp_wrot_write_frame_done = <0x16>;
			mm_na_base = <0x14020000 0x03 0xffff0000>;
			mmsys_config_base = <0x14000000 0x01 0xffff0000>;
			msdc0_base = <0x11230000 0x13 0xffff0000>;
			msdc1_base = <0x11240000 0x14 0xffff0000>;
			msdc2_base = <0x11250000 0x15 0xffff0000>;
			msdc3_base = <0x11260000 0x16 0xffff0000>;
			pwm_sw_base = <0x1100e000 0x63 0xfffff000>;
			reg = <0x10217000 0x1000>;
			scp_base = <0x10050000 0x0d 0xffff0000>;
			scp_sram_base = <0x10020000 0x0a 0xffff0000>;
			seninf_cam0_fifo_full = <0x49>;
			seninf_cam1_2_3_fifo_full = <0x48>;
			stream_done_0 = <0x23>;
			stream_done_1 = <0x24>;
			stream_done_2 = <0x25>;
			stream_done_3 = <0x26>;
			stream_done_4 = <0x27>;
			stream_done_5 = <0x28>;
			stream_done_6 = <0x29>;
			stream_done_7 = <0x2a>;
			stream_done_8 = <0x2b>;
			stream_done_9 = <0x2c>;
			topckgen_base = <0x10000000 0x08 0xffff0000>;
			usb0_base = <0x11200000 0x10 0xffff0000>;
			usb_sif_base = <0x11210000 0x11 0xffff0000>;
			vdec_gcon_base = <0x16000000 0x05 0xffff0000>;
			venc_128byte_cnt_done = <0x85>;
			venc_done = <0x81>;
			venc_gcon_base = <0x17000000 0x06 0xffff0000>;
			venc_mb_done = <0x84>;
		};

		gcpu@10216000 {
			compatible = "mediatek,gcpu";
			interrupts = <0x00 0x96 0x08>;
			reg = <0x10216000 0x1000>;
		};

		gpio {
			GPIO_CMDAT1 = <0x2b>;
			GPIO_SIM1_SCLK = <0xa3>;
			GPIO_SIM1_SIO = <0xa5>;
			GPIO_SIM1_SRST = <0xa4>;
			GPIO_SIM2_SCLK = <0xa0>;
			GPIO_SIM2_SIO = <0xa2>;
			GPIO_SIM2_SRST = <0xa1>;
			compatible = "mediatek,gpio_usage_mapping";
		};

		gpio@10211000 {
			compatible = "mediatek,gpio";
			reg = <0x10211000 0x1000>;
		};

		gps {
			compatible = "mediatek,mt3326-gps";
		};

		hacc@10008000 {
			compatible = "mediatek,hacc";
			interrupts = <0x00 0xae 0x08>;
			reg = <0x10008000 0x1000>;
		};

		i2c@11007000 {
			#address-cells = <0x01>;
			#size-cells = <0x00>;
			cell-index = <0x00>;
			clock-div = <0x01>;
			clock-frequency = <0x3520>;
			clock-names = "i2c0-main\0i2c0-dma";
			clocks = <0x02 0x18 0x02 0x0d>;
			compatible = "mediatek,mt6735-i2c";
			def_speed = <0x64>;
			interrupts = <0x00 0x54 0x08 0x00 0x63 0x08>;
			reg = <0x11007000 0x1000>;

			cam_cal_drv@12 {
				compatible = "mediatek,cam_cal_drv";
				reg = <0x12>;
				status = "okay";
			};

			camera_main@10 {
				compatible = "mediatek,camera_main";
				reg = <0x10>;
				status = "okay";
			};

			camera_main_af@0c {
				compatible = "mediatek,camera_main_af";
				reg = <0x0c>;
				status = "okay";
			};

			camera_sub@3c {
				compatible = "mediatek,camera_sub";
				reg = <0x3c>;
				status = "okay";
			};
		};

		i2c@11008000 {
			#address-cells = <0x01>;
			#size-cells = <0x00>;
			cell-index = <0x01>;
			clock-div = <0x01>;
			clock-frequency = <0x3520>;
			clock-names = "i2c1-main\0i2c1-dma";
			clocks = <0x02 0x19 0x02 0x0d>;
			compatible = "mediatek,mt6735-i2c";
			def_speed = <0x64>;
			interrupts = <0x00 0x55 0x08 0x00 0x64 0x08>;
			reg = <0x11008000 0x1000>;

			fts_touch@38 {
				compatible = "mediatek,fts_touch";
				reg = <0x38>;
				status = "okay";
			};

			gt_touch@5d {
				compatible = "mediatek,gt_touch";
				reg = <0x5d>;
				status = "okay";
			};

			i2c_lcd_bias@3e {
				compatible = "mediatek,i2c_lcd_bias";
				reg = <0x3e>;
				status = "okay";
			};
		};

		i2c@11009000 {
			#address-cells = <0x01>;
			#size-cells = <0x00>;
			cell-index = <0x02>;
			clock-div = <0x01>;
			clock-frequency = <0x3520>;
			clock-names = "i2c2-main\0i2c2-dma";
			clocks = <0x02 0x1a 0x02 0x0d>;
			compatible = "mediatek,mt6735-i2c";
			def_speed = <0x64>;
			interrupts = <0x00 0x56 0x08 0x00 0x65 0x08>;
			reg = <0x11009000 0x1000>;

			alsps@23 {
				compatible = "mediatek,alsps";
				reg = <0x23>;
				status = "okay";
			};

			gsensor@0f {
				compatible = "mediatek,gsensor";
				reg = <0x0f>;
				status = "okay";
			};

			gyro@68 {
				compatible = "mediatek,gyro";
				reg = <0x68>;
				status = "okay";
			};

			msensor@0c {
				compatible = "mediatek,msensor";
				reg = <0x0c>;
				status = "okay";
			};

			nfc@28 {
				compatible = "mediatek,nfc";
				reg = <0x28>;
				status = "okay";
			};

			strobe_main@63 {
				compatible = "mediatek,strobe_main";
				reg = <0x63>;
				status = "okay";
			};
		};

		i2c@1100f000 {
			#address-cells = <0x01>;
			#size-cells = <0x00>;
			cell-index = <0x03>;
			clock-div = <0x01>;
			clock-frequency = <0x3520>;
			clock-names = "i2c3-main\0i2c3-dma";
			clocks = <0x02 0x1b 0x02 0x0d>;
			compatible = "mediatek,mt6735-i2c";
			def_speed = <0x64>;
			interrupts = <0x00 0x57 0x08 0x00 0x66 0x08>;
			reg = <0x1100f000 0x1000>;
		};

		i2c@11010000 {
			#address-cells = <0x01>;
			#size-cells = <0x00>;
			cell-index = <0x04>;
			clock-div = <0x01>;
			clock-frequency = <0x3520>;
			clock-names = "i2c4-main\0i2c4-dma";
			clocks = <0x02 0x1b 0x02 0x0d>;
			compatible = "mediatek,mt6735-i2c";
			def_speed = <0x64>;
			reg = <0xa7ffd0 0x1000>;
		};

		imgsys@15000000 {
			#clock-cells = <0x01>;
			compatible = "mediatek,mt6735-imgsys";
			linux,phandle = <0x1c>;
			phandle = <0x1c>;
			reg = <0x15000000 0x1000>;
		};

		infracfg_ao@10000000 {
			compatible = "mediatek,infracfg_ao";
			reg = <0x10000000 0x1000>;
		};

		infrasys@10000000 {
			#clock-cells = <0x01>;
			compatible = "mediatek,mt6735-infrasys";
			linux,phandle = <0x19>;
			phandle = <0x19>;
			reg = <0x10000000 0x1000>;
		};

		irlearning-spi {
			compatible = "mediatek,irlearning-spi";
			spi_clock = <0x67f3540>;
			spi_cs_invert = <0x01>;
			spi_data_invert = <0x00>;
		};

		irtx-pwm {
			compatible = "mediatek,irtx-pwm";
			pwm_ch = <0x02>;
			pwm_data_invert = <0x00>;
		};

		irtx@11011000 {
			clock-div = <0x01>;
			clock-frequency = <0x18cba80>;
			clock-names = "clk-irtx-main";
			clocks = <0x02 0x1e>;
			compatible = "mediatek,irtx";
			interrupts = <0x00 0x7c 0x04>;
			pinctrl-0 = <0x1f>;
			pinctrl-1 = <0x20>;
			pinctrl-names = "irtx_gpio_default\0irtx_gpio_led_set";
			pwm_ch = <0x00>;
			reg = <0x11011000 0x1000>;
			status = "okay";
		};

		ispsys@15000000 {
			clock-names = "CG_SCP_SYS_DIS\0CG_SCP_SYS_ISP\0CG_DISP0_SMI_COMMON\0CG_IMAGE_CAM_SMI\0CG_IMAGE_CAM_CAM\0CG_IMAGE_SEN_TG\0CG_IMAGE_SEN_CAM\0CG_IMAGE_CAM_SV\0CG_IMAGE_LARB2_SMI";
			clocks = <0x13 0x04 0x13 0x06 0x1a 0x01 0x1c 0x02 0x1c 0x03 0x1c 0x04 0x1c 0x05 0x1c 0x06 0x1c 0x01>;
			compatible = "mediatek,mt6735-ispsys";
			interrupts = <0x00 0xb7 0x08 0x00 0xb8 0x08 0x00 0xb9 0x08 0x00 0xce 0x08 0x00 0xcf 0x08>;
			reg = <0x15004000 0x9000 0x1500d000 0x1000 0x15000000 0x10000 0x10215000 0x3000 0x10211000 0x1000>;
		};

		jpgdec@17004000 {
			clock-names = "disp-mtcmos\0disp-smi\0venc-mtcmos\0venc-larb\0venc-jpgdec";
			clocks = <0x13 0x04 0x1a 0x01 0x13 0x08 0x1d 0x01 0x1d 0x04>;
			compatible = "mediatek,jpgdec";
			interrupts = <0x00 0xd1 0x08>;
			reg = <0x17004000 0x1000>;
		};

		jpgenc@17003000 {
			clock-names = "disp-mtcmos\0disp-smi\0venc-mtcmos\0venc-larb\0venc-jpgenc";
			clocks = <0x13 0x04 0x1a 0x01 0x13 0x08 0x1d 0x01 0x1d 0x03>;
			compatible = "mediatek,jpgenc";
			interrupts = <0x00 0xb5 0x08>;
			reg = <0x17003000 0x1000>;
		};

		kd_camera_hw1@15008000 {
			clock-names = "TOP_CAMTG_SEL\0TOP_UNIVPLL_D26\0TOP_UNIVPLL2_D2";
			clocks = <0x03 0x08 0x03 0x3f 0x03 0x44>;
			compatible = "mediatek,camera_hw";
			pinctrl-0 = <0x57>;
			pinctrl-1 = <0x58>;
			pinctrl-10 = <0x61>;
			pinctrl-11 = <0x60>;
			pinctrl-12 = <0x61>;
			pinctrl-13 = <0x60>;
			pinctrl-14 = <0x61>;
			pinctrl-15 = <0x62>;
			pinctrl-16 = <0x63>;
			pinctrl-17 = <0x64>;
			pinctrl-18 = <0x65>;
			pinctrl-19 = <0x66>;
			pinctrl-2 = <0x59>;
			pinctrl-3 = <0x5a>;
			pinctrl-4 = <0x5b>;
			pinctrl-5 = <0x5c>;
			pinctrl-6 = <0x5d>;
			pinctrl-7 = <0x5e>;
			pinctrl-8 = <0x5f>;
			pinctrl-9 = <0x60>;
			pinctrl-names = "default\0cam0_rst0\0cam0_rst1\0cam0_pnd0\0cam0_pnd1\0cam1_rst0\0cam1_rst1\0cam1_pnd0\0cam1_pnd1\0cam_ldo0_0\0cam_ldo0_1\0cam_ldo1_0\0cam_ldo1_1\0cam_ldo2_0\0cam_ldo2_1\0flashlight_enable_0\0flashlight_enable_1\0flashlight_mode_0\0flashlight_mode_1\0flashlight_mode_pwm";
			reg = <0x15008000 0x1000>;
			status = "okay";
			vcama-supply = <0x53>;
			vcama_main2-supply = <0x53>;
			vcama_sub-supply = <0x53>;
			vcamaf-supply = <0x55>;
			vcamaf_main2-supply = <0x55>;
			vcamaf_sub-supply = <0x55>;
			vcamd-supply = <0x54>;
			vcamd_main2-supply = <0x54>;
			vcamd_sub-supply = <0x54>;
			vcamio-supply = <0x56>;
			vcamio_main2-supply = <0x56>;
			vcamio_sub-supply = <0x56>;
		};

		kd_camera_hw2@15008000 {
			compatible = "mediatek,camera_hw2";
			reg = <0x15008000 0x1000>;
		};

		keypad@10003000 {
			compatible = "mediatek,mt6735-keypad";
			interrupts = <0x00 0xa4 0x02>;
			mediatek,kpd-hw-dl-key0 = <0x01>;
			mediatek,kpd-hw-dl-key1 = <0x11>;
			mediatek,kpd-hw-dl-key2 = <0x08>;
			mediatek,kpd-hw-factory-key = <0x11>;
			mediatek,kpd-hw-init-map = <0x00 0x73 0x00 0x00 0x00 0x00 0x00 0x00 0x00 0x00 0x00 0x00 0x00 0x00 0x00 0x00 0x00 0x00 0x00 0x00 0x00 0x00 0x00 0x00 0x00 0x00 0x00 0x00 0x00 0x00 0x00 0x00 0x00 0x00 0x00 0x00 0x00 0x00 0x00 0x00 0x00 0x00 0x00 0x00 0x00 0x00 0x00 0x00 0x00 0x00 0x00 0x00 0x00 0x00 0x00 0x00 0x00 0x00 0x00 0x00 0x00 0x00 0x00 0x00 0x00 0x00 0x00 0x00 0x00 0x00 0x00 0x00>;
			mediatek,kpd-hw-map-num = <0x48>;
			mediatek,kpd-hw-pwrkey = <0x08>;
			mediatek,kpd-hw-recovery-key = <0x01>;
			mediatek,kpd-hw-rstkey = <0x11>;
			mediatek,kpd-key-debounce = <0x400>;
			mediatek,kpd-pwkey-gpio-din = <0x00>;
			mediatek,kpd-pwrkey-eint-gpio = <0x00>;
			mediatek,kpd-sw-pwrkey = <0x74>;
			mediatek,kpd-sw-rstkey = <0x72>;
			mediatek,kpd-use-extend-type = <0x00>;
			reg = <0x10003000 0x1000>;
			status = "okay";
		};

		lastpc@10200000 {
			compatible = "mediatek,mt6735-mcucfg";
			interrupts = <0x00 0x47 0x04>;
			reg = <0x10200000 0x200>;
		};

		lcm_mode {
			compatible = "mediatek,lcm_mode";
			lcm_bl_gpio = <0x0b 0x81 0x00>;
			lcm_power_gpio = <0x0b 0x50 0x00>;
			pinctrl-0 = <0x4a>;
			pinctrl-1 = <0x4b>;
			pinctrl-2 = <0x4c>;
			pinctrl-3 = <0x4d>;
			pinctrl-4 = <0x4e>;
			pinctrl-5 = <0x4f>;
			pinctrl-6 = <0x50>;
			pinctrl-7 = <0x51>;
			pinctrl-8 = <0x52>;
			pinctrl-names = "default\0lcm_mode_00\0lcm_mode_01\0lcm_mode_02\0lcm_mode_03\0lcm_mode_04\0lcm_mode_05\0lcm_mode_06\0lcm_mode_07";
			status = "okay";
		};

		m4u@10205000 {
			cell-index = <0x00>;
			clock-names = "infra_m4u\0smi_common\0m4u_disp0_smi_larb0\0m4u_vdec0_vdec\0m4u_vdec1_larb\0m4u_img_image_larb2_smi\0m4u_venc_venc\0m4u_venc_larb";
			clocks = <0x19 0x09 0x1a 0x01 0x1a 0x02 0x1b 0x01 0x1b 0x02 0x1c 0x01 0x1d 0x02 0x1d 0x01>;
			compatible = "mediatek,m4u";
			interrupts = <0x00 0x92 0x08>;
			reg = <0x10205000 0x1000>;
		};

		mali@13040000 {
			clock-frequency = <0x1ad27480>;
			clock-names = "mfg-main\0mfg-smi-common\0mtcmos-mfg\0mtcmos-display";
			clocks = <0x49 0x01 0x1a 0x01 0x13 0x05 0x13 0x04>;
			compatible = "arm,malit720\0arm,mali-t72x\0arm,malit7xx\0arm,mali-midgard";
			interrupt-names = "JOB\0MMU\0GPU";
			interrupts = <0x00 0xd4 0x08 0x00 0xd3 0x08 0x00 0xd2 0x08>;
			reg = <0x13040000 0x4000>;
		};

		mcu_biu@10300000 {
			compatible = "mediatek,mt6735-mcu_biu";
			reg = <0x10300000 0x8000>;
		};

		mcucfg@10200000 {
			compatible = "mediatek,mcucfg";
			interrupts = <0x00 0x47 0x04>;
			reg = <0x10200000 0x200>;
		};

		mdc2k@3a00b01c {
			clock-names = "scp-sys-md2-main";
			clocks = <0x13 0x02>;
			compatible = "mediatek,mdc2k";
			interrupts = <0x00 0xe5 0x02>;
			reg = <0x3a00b01c 0x10 0x1021c800 0x300 0x1021d800 0x300>;
		};

		mdcldma@1000A000 {
			clock-names = "scp-sys-md1-main";
			clocks = <0x13 0x01>;
			compatible = "mediatek,mdcldma";
			interrupts = <0x00 0x91 0x04 0x00 0x8c 0x08 0x00 0xdd 0x02>;
			mediatek,cldma_capability = <0x06>;
			mediatek,md_id = <0x00>;
			mediatek,md_smem_size = <0x10000>;
			pinctrl-0 = <0x14>;
			pinctrl-1 = <0x15>;
			pinctrl-2 = <0x16>;
			pinctrl-3 = <0x17>;
			pinctrl-4 = <0x18>;
			pinctrl-names = "default\0vsram_output_low\0vsram_output_high\0RFIC0_01_mode\0RFIC0_04_mode";
			reg = <0x1000a000 0x1000 0x1000b000 0x1000 0x1021a000 0x1000 0x1021b000 0x1000 0x1020a000 0x1000 0x1020b000 0x1000>;
		};

		mdp_rdma@14001000 {
			clock-names = "MDP_RDMA";
			clocks = <0x1a 0x04>;
			compatible = "mediatek,mdp_rdma";
			interrupts = <0x00 0xbb 0x08>;
			reg = <0x14001000 0x1000>;
		};

		mdp_rsz0@14002000 {
			clock-names = "MDP_RSZ0";
			clocks = <0x1a 0x05>;
			compatible = "mediatek,mdp_rsz0";
			interrupts = <0x00 0xbc 0x08>;
			reg = <0x14002000 0x1000>;
		};

		mdp_rsz1@14003000 {
			clock-names = "MDP_RSZ1";
			clocks = <0x1a 0x06>;
			compatible = "mediatek,mdp_rsz1";
			interrupts = <0x00 0xbd 0x08>;
			reg = <0x14003000 0x1000>;
		};

		mdp_tdshp@14006000 {
			clock-names = "MDP_TDSHP";
			clocks = <0x1a 0x07>;
			compatible = "mediatek,mdp_tdshp";
			interrupts = <0x00 0xbe 0x08>;
			reg = <0x14006000 0x1000>;
		};

		mdp_wdma@14004000 {
			clock-names = "MDP_WDMA";
			clocks = <0x1a 0x08>;
			compatible = "mediatek,mdp_wdma";
			interrupts = <0x00 0xbf 0x08>;
			reg = <0x14004000 0x1000>;
		};

		mdp_wrot@14005000 {
			clock-names = "MDP_WROT";
			clocks = <0x1a 0x09>;
			compatible = "mediatek,mdp_wrot";
			interrupts = <0x00 0xc0 0x08>;
			reg = <0x14005000 0x1000>;
		};

		met_smi@14016000 {
			clock-names = "smi-common\0smi-larb0\0img-larb2\0vdec0-vdec\0vdec1-larb\0venc-larb\0venc-venc";
			clocks = <0x1a 0x01 0x1a 0x02 0x1c 0x01 0x1b 0x01 0x1b 0x02 0x1d 0x01 0x1d 0x02>;
			compatible = "mediatek,met_smi";
			reg = <0x14016000 0x1000 0x14015000 0x1000 0x16010000 0x1000 0x15001000 0x1000 0x17001000 0x1000>;
		};

		mfgsys@13000000 {
			#clock-cells = <0x01>;
			compatible = "mediatek,mt6735-mfgsys";
			linux,phandle = <0x49>;
			phandle = <0x49>;
			reg = <0x13000000 0x1000>;
		};

		mhl@0 {
			compatible = "mediatek,sii8348-hdmi";
		};

		mmsys@14000000 {
			#clock-cells = <0x01>;
			compatible = "mediatek,mt6735-mmsys";
			linux,phandle = <0x1a>;
			phandle = <0x1a>;
			reg = <0x14000000 0x1000>;
		};

		mmsys_config@14000000 {
			clock-names = "CAM_MDP";
			clocks = <0x1a 0x03>;
			compatible = "mediatek,mmsys_config";
			interrupts = <0x00 0xcd 0x08>;
			reg = <0x14000000 0x1000>;
		};

		mt_pmic_regulator {
			compatible = "mediatek,mt_pmic";

			buck_regulators {
				compatible = "mediatek,mt_pmic_buck_regulators";

				buck_vcore1 {
					regulator-always-on;
					regulator-boot-on;
					regulator-enable-ramp-delay = <0xb4>;
					regulator-max-microvolt = <0x154456>;
					regulator-min-microvolt = <0x927c0>;
					regulator-name = "vcore1";
					regulator-ramp-delay = <0x186a>;
				};

				buck_vlte {
					regulator-always-on;
					regulator-boot-on;
					regulator-enable-ramp-delay = <0xb4>;
					regulator-max-microvolt = <0x154456>;
					regulator-min-microvolt = <0x927c0>;
					regulator-name = "vlte";
					regulator-ramp-delay = <0x186a>;
				};

				buck_vpa {
					regulator-enable-ramp-delay = <0xb4>;
					regulator-max-microvolt = <0x37b1d0>;
					regulator-min-microvolt = <0x7a120>;
					regulator-name = "vpa";
					regulator-ramp-delay = <0xc350>;
				};

				buck_vproc {
					regulator-always-on;
					regulator-boot-on;
					regulator-enable-ramp-delay = <0xb4>;
					regulator-max-microvolt = <0x154456>;
					regulator-min-microvolt = <0x927c0>;
					regulator-name = "vproc";
					regulator-ramp-delay = <0x186a>;
				};

				buck_vsys22 {
					regulator-always-on;
					regulator-boot-on;
					regulator-enable-ramp-delay = <0xb4>;
					regulator-max-microvolt = <0x1e6c16>;
					regulator-min-microvolt = <0x124f80>;
					regulator-name = "vsys22";
					regulator-ramp-delay = <0x186a>;
				};
			};

			ldo_regulators {
				compatible = "mediatek,mt_pmic_ldo_regulators";

				ldo_vaud28 {
					linux,phandle = <0x7f>;
					phandle = <0x7f>;
					regulator-boot-on;
					regulator-enable-ramp-delay = <0x108>;
					regulator-max-microvolt = <0x2ab980>;
					regulator-min-microvolt = <0x2ab980>;
					regulator-name = "vaud28";
				};

				ldo_vaux18 {
					linux,phandle = <0x7c>;
					phandle = <0x7c>;
					regulator-boot-on;
					regulator-enable-ramp-delay = <0x108>;
					regulator-max-microvolt = <0x1b7740>;
					regulator-min-microvolt = <0x1b7740>;
					regulator-name = "vaux18";
				};

				ldo_vcama {
					linux,phandle = <0x53>;
					phandle = <0x53>;
					regulator-default-on = <0x00>;
					regulator-enable-ramp-delay = <0x108>;
					regulator-max-microvolt = <0x2ab980>;
					regulator-min-microvolt = <0x16e360>;
					regulator-name = "vcama";
					status = "okay";
				};

				ldo_vcamaf {
					linux,phandle = <0x55>;
					phandle = <0x55>;
					regulator-default-on = <0x00>;
					regulator-enable-ramp-delay = <0x108>;
					regulator-max-microvolt = <0x325aa0>;
					regulator-min-microvolt = <0x124f80>;
					regulator-name = "vcamaf";
					status = "okay";
				};

				ldo_vcamd {
					linux,phandle = <0x54>;
					phandle = <0x54>;
					regulator-default-on = <0x00>;
					regulator-enable-ramp-delay = <0x108>;
					regulator-max-microvolt = <0x16e360>;
					regulator-min-microvolt = <0xdbba0>;
					regulator-name = "vcamd";
					status = "okay";
				};

				ldo_vcamio {
					linux,phandle = <0x56>;
					phandle = <0x56>;
					regulator-default-on = <0x00>;
					regulator-enable-ramp-delay = <0xdc>;
					regulator-max-microvolt = <0x1b7740>;
					regulator-min-microvolt = <0x124f80>;
					regulator-name = "vcamio";
					status = "okay";
				};

				ldo_vcn18 {
					linux,phandle = <0x67>;
					phandle = <0x67>;
					regulator-enable-ramp-delay = <0x2c>;
					regulator-max-microvolt = <0x1b7740>;
					regulator-min-microvolt = <0x1b7740>;
					regulator-name = "vcn18";
				};

				ldo_vcn28 {
					linux,phandle = <0x68>;
					phandle = <0x68>;
					regulator-enable-ramp-delay = <0x108>;
					regulator-max-microvolt = <0x2ab980>;
					regulator-min-microvolt = <0x2ab980>;
					regulator-name = "vcn28";
				};

				ldo_vcn33_bt {
					linux,phandle = <0x69>;
					phandle = <0x69>;
					regulator-enable-ramp-delay = <0x108>;
					regulator-max-microvolt = <0x36ee80>;
					regulator-min-microvolt = <0x325aa0>;
					regulator-name = "vcn33_bt";
				};

				ldo_vcn33_wifi {
					linux,phandle = <0x6a>;
					phandle = <0x6a>;
					regulator-enable-ramp-delay = <0x108>;
					regulator-max-microvolt = <0x36ee80>;
					regulator-min-microvolt = <0x325aa0>;
					regulator-name = "vcn33_wifi";
				};

				ldo_vefuse {
					linux,phandle = <0x80>;
					phandle = <0x80>;
					regulator-enable-ramp-delay = <0x108>;
					regulator-max-microvolt = <0x2191c0>;
					regulator-min-microvolt = <0x1b7740>;
					regulator-name = "vefuse";
				};

				ldo_vemc_3v3 {
					linux,phandle = <0x83>;
					phandle = <0x83>;
					regulator-boot-on;
					regulator-enable-ramp-delay = <0x108>;
					regulator-max-microvolt = <0x325aa0>;
					regulator-min-microvolt = <0x1b7740>;
					regulator-name = "vemc_3v3";
				};

				ldo_vgp1 {
					linux,phandle = <0x6f>;
					phandle = <0x6f>;
					regulator-default-on = <0x00>;
					regulator-enable-ramp-delay = <0x108>;
					regulator-max-microvolt = <0x325aa0>;
					regulator-min-microvolt = <0x124f80>;
					regulator-name = "vgp1";
					status = "okay";
				};

				ldo_vibr {
					linux,phandle = <0x88>;
					phandle = <0x88>;
					regulator-default-on = <0x00>;
					regulator-enable-ramp-delay = <0x2c>;
					regulator-max-microvolt = <0x325aa0>;
					regulator-min-microvolt = <0x124f80>;
					regulator-name = "vibr";
					status = "okay";
				};

				ldo_vio18 {
					linux,phandle = <0x8b>;
					phandle = <0x8b>;
					regulator-boot-on;
					regulator-enable-ramp-delay = <0x108>;
					regulator-max-microvolt = <0x1b7740>;
					regulator-min-microvolt = <0x1b7740>;
					regulator-name = "vio18";
				};

				ldo_vio28 {
					linux,phandle = <0x87>;
					phandle = <0x87>;
					regulator-boot-on;
					regulator-enable-ramp-delay = <0x108>;
					regulator-max-microvolt = <0x2ab980>;
					regulator-min-microvolt = <0x2ab980>;
					regulator-name = "vio28";
				};

				ldo_vm {
					linux,phandle = <0x8d>;
					phandle = <0x8d>;
					regulator-boot-on;
					regulator-enable-ramp-delay = <0x108>;
					regulator-max-microvolt = <0x177fa0>;
					regulator-min-microvolt = <0x12ebc0>;
					regulator-name = "vm";
				};

				ldo_vmc {
					linux,phandle = <0x86>;
					phandle = <0x86>;
					regulator-boot-on;
					regulator-enable-ramp-delay = <0x2c>;
					regulator-max-microvolt = <0x325aa0>;
					regulator-min-microvolt = <0x1b7740>;
					regulator-name = "vmc";
				};

				ldo_vmch {
					linux,phandle = <0x84>;
					phandle = <0x84>;
					regulator-boot-on;
					regulator-enable-ramp-delay = <0x2c>;
					regulator-max-microvolt = <0x325aa0>;
					regulator-min-microvolt = <0x2c4020>;
					regulator-name = "vmch";
				};

				ldo_vrf18_0 {
					linux,phandle = <0x89>;
					phandle = <0x89>;
					regulator-enable-ramp-delay = <0xdc>;
					regulator-max-microvolt = <0x1bd8e8>;
					regulator-min-microvolt = <0x1bd8e8>;
					regulator-name = "vrf18_0";
				};

				ldo_vrf18_1 {
					linux,phandle = <0x8a>;
					phandle = <0x8a>;
					regulator-enable-ramp-delay = <0xdc>;
					regulator-max-microvolt = <0x1bd8e8>;
					regulator-min-microvolt = <0x124f80>;
					regulator-name = "vrf18_1";
				};

				ldo_vsim1 {
					linux,phandle = <0x81>;
					phandle = <0x81>;
					regulator-default-on = <0x00>;
					regulator-enable-ramp-delay = <0x108>;
					regulator-max-microvolt = <0x200b20>;
					regulator-min-microvolt = <0x19f0a0>;
					regulator-name = "vsim1";
					status = "okay";
				};

				ldo_vsim2 {
					linux,phandle = <0x82>;
					phandle = <0x82>;
					regulator-default-on = <0x00>;
					regulator-enable-ramp-delay = <0x108>;
					regulator-max-microvolt = <0x200b20>;
					regulator-min-microvolt = <0x19f0a0>;
					regulator-name = "vsim2";
					status = "okay";
				};

				ldo_vsram {
					linux,phandle = <0x8c>;
					phandle = <0x8c>;
					regulator-boot-on;
					regulator-enable-ramp-delay = <0xdc>;
					regulator-max-microvolt = <0x16caf6>;
					regulator-min-microvolt = <0xaae60>;
					regulator-name = "vsram";
					regulator-ramp-delay = <0x186a>;
				};

				ldo_vtcxo_0 {
					linux,phandle = <0x7d>;
					phandle = <0x7d>;
					regulator-boot-on;
					regulator-enable-ramp-delay = <0x6e>;
					regulator-max-microvolt = <0x2ab980>;
					regulator-min-microvolt = <0x2ab980>;
					regulator-name = "vtcxo_0";
				};

				ldo_vtcxo_1 {
					linux,phandle = <0x7e>;
					phandle = <0x7e>;
					regulator-enable-ramp-delay = <0x6e>;
					regulator-max-microvolt = <0x2ab980>;
					regulator-min-microvolt = <0x2ab980>;
					regulator-name = "vtcxo_1";
				};

				ldo_vtref {
					linux,phandle = <0x85>;
					phandle = <0x85>;
					regulator-enable-ramp-delay = <0xf0>;
					regulator-max-microvolt = <0x1b7740>;
					regulator-min-microvolt = <0x1b7740>;
					regulator-name = "vtref";
				};

				ldo_vusb33 {
					linux,phandle = <0x35>;
					phandle = <0x35>;
					regulator-boot-on;
					regulator-enable-ramp-delay = <0x108>;
					regulator-max-microvolt = <0x325aa0>;
					regulator-min-microvolt = <0x325aa0>;
					regulator-name = "vusb33";
				};
			};

			regulators_supply {
				compatible = "mediatek,mt_pmic_regulator_supply";
				vaud28-supply = <0x7f>;
				vaux18-supply = <0x7c>;
				vefuse-supply = <0x80>;
				vemc_3v3-supply = <0x83>;
				vibr-supply = <0x88>;
				vio18-supply = <0x8b>;
				vio28-supply = <0x87>;
				vm-supply = <0x8d>;
				vmc-supply = <0x86>;
				vmch-supply = <0x84>;
				vrf18_0-supply = <0x89>;
				vrf18_1-supply = <0x8a>;
				vsim1-supply = <0x81>;
				vsim2-supply = <0x82>;
				vsram-supply = <0x8c>;
				vtcxo_0-supply = <0x7d>;
				vtcxo_1-supply = <0x7e>;
				vtref-supply = <0x85>;
			};
		};

		mt_soc_codec_dummy_name {
			compatible = "mediatek,mt_soc_codec_dummy";
		};

		mt_soc_codec_name {
			compatible = "mediatek,mt_soc_codec_63xx";
		};

		mt_soc_dai_name {
			compatible = "mediatek,mt_soc_dai_stub";
		};

		mt_soc_dl1_awb_pcm {
			compatible = "mediatek,mt_soc_pcm_dl1_awb";
		};

		mt_soc_dl1_pcm@11220000 {
			audclk-gpio = <0x8f 0x00>;
			audmiso-gpio = <0x90 0x00>;
			audmosi-gpio = <0x91 0x00>;
			clock-names = "aud_afe_clk\0aud_i2s_clk\0aud_dac_clk\0aud_dac_predis_clk\0aud_adc_clk\0aud_apll22m_clk\0aud_apll24m_clk\0aud_apll1_tuner_clk\0aud_apll2_tuner_clk\0aud_tml_clk\0aud_infra_clk\0aud_mux1_clk\0aud_mux2_clk\0top_ad_apll1_clk\0top_whpll_audio_clk\0top_mux_audio\0top_mux_audio_int\0top_sys_pll1_d4\0apmixed_apll1_clk\0apmixed_apll2_clk\0top_clk26m_clk";
			clocks = <0x3b 0x01 0x3b 0x02 0x3b 0x08 0x3b 0x09 0x3b 0x07 0x3b 0x03 0x3b 0x04 0x3b 0x06 0x3b 0x05 0x3b 0x0a 0x19 0x06 0x03 0x19 0x03 0x1a 0x03 0x21 0x03 0x4b 0x03 0x11 0x03 0x12 0x03 0x33 0x3c 0x08 0x3c 0x09 0x3d>;
			compatible = "mediatek,mt-soc-dl1-pcm";
			extspkamp-gpio = <0x75 0x00>;
			i2s1clk-gpio = <0x50 0x00>;
			i2s1dat-gpio = <0x4e 0x00>;
			i2s1mclk-gpio = <0x09 0x00>;
			i2s1ws-gpio = <0x4f 0x00>;
			interrupts = <0x00 0x90 0x08>;
			pinctrl-0 = <0x3e>;
			pinctrl-1 = <0x3f>;
			pinctrl-10 = <0x48>;
			pinctrl-2 = <0x40>;
			pinctrl-3 = <0x41>;
			pinctrl-4 = <0x42>;
			pinctrl-5 = <0x43>;
			pinctrl-6 = <0x44>;
			pinctrl-7 = <0x45>;
			pinctrl-8 = <0x46>;
			pinctrl-9 = <0x47>;
			pinctrl-names = "default\0audpmicclk-mode0\0audpmicclk-mode1\0audi2s1-mode0\0audi2s1-mode1\0extamp-pullhigh\0extamp-pulllow\0extamp2-pullhigh\0extamp2-pulllow\0rcvspk-pullhigh\0rcvspk-pulllow";
			reg = <0x11220000 0x1000>;
			status = "okay";
			vowclk-gpio = <0x94 0x00>;
		};

		mt_soc_dl2_pcm {
			compatible = "mediatek,mt_soc_pcm_dl2";
		};

		mt_soc_dummy_pcm {
			compatible = "mediatek,mt_soc_pcm_dummy";
		};

		mt_soc_fm_i2s_awb_pcm {
			compatible = "mediatek,mt_soc_pcm_fm_i2s_awb";
		};

		mt_soc_fm_i2s_pcm {
			compatible = "mediatek,mt_soc_pcm_fm_i2s";
		};

		mt_soc_fm_mrgtx_pcm {
			compatible = "mediatek,mt_soc_pcm_fmtx";
		};

		mt_soc_hdmi_pcm {
			compatible = "mediatek,mt_soc_pcm_hdmi";
		};

		mt_soc_hp_impedance_pcm {
			compatible = "mediatek,Mt_soc_pcm_hp_impedance";
		};

		mt_soc_i2s0_awb_pcm {
			compatible = "mediatek,mt_soc_pcm_i2s0_awb";
		};

		mt_soc_i2s0_pcm {
			compatible = "mediatek,mt_soc_pcm_dl1_i2s0";
		};

		mt_soc_i2s0dl1_pcm {
			compatible = "mediatek,mt_soc_pcm_dl1_i2s0Dl1";
		};

		mt_soc_mrgrx_awb_pcm {
			compatible = "mediatek,mt_soc_pcm_mrgrx_awb";
		};

		mt_soc_mrgrx_pcm {
			compatible = "mediatek,mt_soc_pcm_mrgrx";
		};

		mt_soc_offload_gdma {
			compatible = "mediatek,mt_soc_pcm_offload_gdma";
		};

		mt_soc_routing_dai_name {
			compatible = "mediatek,mt_soc_dai_routing";
		};

		mt_soc_routing_pcm {
			compatible = "mediatek,mt_soc_pcm_routing";
			i2s1clk-gpio = <0x07 0x06>;
			i2s1dat-gpio = <0x05 0x06>;
			i2s1mclk-gpio = <0x09 0x06>;
			i2s1ws-gpio = <0x06 0x06>;
		};

		mt_soc_tdmrx_pcm {
			compatible = "mediatek,mt_soc_tdm_capture";
		};

		mt_soc_ul1_pcm {
			compatible = "mediatek,mt_soc_pcm_capture";
		};

		mt_soc_ul2_pcm {
			compatible = "mediatek,mt_soc_pcm_capture2";
		};

		mt_soc_uldlloopback_pcm {
			compatible = "mediatek,mt_soc_pcm_uldlloopback";
		};

		mt_soc_voice_md1 {
			compatible = "mediatek,mt_soc_pcm_voice_md1";
		};

		mt_soc_voice_md1_bt {
			compatible = "mediatek,mt_soc_pcm_voice_md1_bt";
		};

		mt_soc_voice_md2 {
			compatible = "mediatek,mt_soc_pcm_voice_md2";
		};

		mt_soc_voice_md2_bt {
			compatible = "mediatek,mt_soc_pcm_voice_md2_bt";
		};

		mt_soc_voip_bt_in {
			compatible = "mediatek,mt_soc_pcm_bt_dai";
		};

		mt_soc_voip_bt_out {
			compatible = "mediatek,mt_soc_pcm_dl1_bt";
		};

		mtkfb@7e000000 {
			compatible = "mediatek,mtkfb";
			reg = <0x7e000000 0x1000000>;
		};

		nfc {
			compatible = "mediatek,nfc-gpio-v2";
			debounce = <0x02 0x00>;
			gpio-eint = <0x01>;
			gpio-irq = <0x02>;
			gpio-rst = <0x03>;
			gpio-ven = <0x04>;
			interrupt-parent = <0x0c>;
			interrupts = <0x02 0x04>;
			status = "okay";
		};

		pericfg@10002000 {
			compatible = "mediatek,pericfg";
			reg = <0x10002000 0x1000>;
		};

		perisys@10002000 {
			#clock-cells = <0x01>;
			compatible = "mediatek,mt6735-perisys";
			linux,phandle = <0x02>;
			phandle = <0x02>;
			reg = <0x10002000 0x1000>;
		};

		pinctrl@10211000 {
			#gpio-cells = <0x02>;
			compatible = "mediatek,mt6735-pinctrl";
			gpio-controller;
			linux,phandle = <0x0b>;
			mediatek,pctl-regmap = <0x1e>;
			phandle = <0x0b>;
			pins-are-numbered;
			reg = <0x00 0x9bceb8 0x00 0x3e8>;

			8193ckgen_default {
				linux,phandle = <0x93>;
				phandle = <0x93>;
			};

			8193ckgen_dpi {
				linux,phandle = <0x95>;
				phandle = <0x95>;

				pins_cmd_dat {
					pins = <0x02>;
				};
			};

			8193ckgen_gpio {
				linux,phandle = <0x94>;
				phandle = <0x94>;

				pins_cmd_dat {
					bias-pull-up = <0x00>;
					output-high;
					pins = <0x00>;
					slew-rate = <0x01>;
				};
			};

			alspsdefaultcfg {
				linux,phandle = <0x8f>;
				phandle = <0x8f>;
			};

			alspspincfg {
				linux,phandle = <0x90>;
				phandle = <0x90>;

				pins_cmd_dat {
					bias-pull-up = <0x00>;
					pins = <0x300>;
					slew-rate = <0x00>;
				};
			};

			audexam2phigh {
				linux,phandle = <0x45>;
				phandle = <0x45>;

				pins_cmd_dat {
					output-high;
					pins = <0x8000>;
					slew-rate = <0x01>;
				};
			};

			audexamp2low {
				linux,phandle = <0x46>;
				phandle = <0x46>;

				pins_cmd_dat {
					output-low;
					pins = <0x8000>;
					slew-rate = <0x01>;
				};
			};

			audexamphigh {
				linux,phandle = <0x43>;
				phandle = <0x43>;

				pins_cmd_dat {
					output-high;
					pins = <0x8100>;
					slew-rate = <0x01>;
				};
			};

			audexamplow {
				linux,phandle = <0x44>;
				phandle = <0x44>;

				pins_cmd_dat {
					output-low;
					pins = <0x8100>;
					slew-rate = <0x01>;
				};
			};

			audi2s1mode0 {
				linux,phandle = <0x41>;
				phandle = <0x41>;

				pins_cmd0_dat {
					pins = <0x4e00>;
				};

				pins_cmd1_dat {
					pins = <0x4f00>;
				};

				pins_cmd2_dat {
					pins = <0x5000>;
				};
			};

			audi2s1mode1 {
				linux,phandle = <0x42>;
				phandle = <0x42>;

				pins_cmd0_dat {
					pins = <0x4e01>;
				};

				pins_cmd1_dat {
					pins = <0x4f01>;
				};

				pins_cmd2_dat {
					pins = <0x5001>;
				};
			};

			audiodefault {
				linux,phandle = <0x3e>;
				phandle = <0x3e>;
			};

			audrcvspkhigh {
				linux,phandle = <0x47>;
				phandle = <0x47>;

				pins_cmd_dat {
					output-high;
					pins = <0x7800>;
					slew-rate = <0x01>;
				};
			};

			audrcvspklow {
				linux,phandle = <0x48>;
				phandle = <0x48>;

				pins_cmd_dat {
					output-low;
					pins = <0x7800>;
					slew-rate = <0x01>;
				};
			};

			cam0@0 {
				linux,phandle = <0x58>;
				phandle = <0x58>;

				pins_cmd_dat {
					output-low;
					pins = <0x900>;
					slew-rate = <0x01>;
				};
			};

			cam0@1 {
				linux,phandle = <0x59>;
				phandle = <0x59>;

				pins_cmd_dat {
					output-high;
					pins = <0x900>;
					slew-rate = <0x01>;
				};
			};

			cam0@2 {
				linux,phandle = <0x5a>;
				phandle = <0x5a>;

				pins_cmd_dat {
					output-low;
					pins = <0xc00>;
					slew-rate = <0x01>;
				};
			};

			cam0@3 {
				linux,phandle = <0x5b>;
				phandle = <0x5b>;

				pins_cmd_dat {
					output-high;
					pins = <0xc00>;
					slew-rate = <0x01>;
				};
			};

			cam1@0 {
				linux,phandle = <0x5c>;
				phandle = <0x5c>;

				pins_cmd_dat {
					output-low;
					pins = <0xb00>;
					slew-rate = <0x01>;
				};
			};

			cam1@1 {
				linux,phandle = <0x5d>;
				phandle = <0x5d>;

				pins_cmd_dat {
					output-high;
					pins = <0xb00>;
					slew-rate = <0x01>;
				};
			};

			cam1@2 {
				linux,phandle = <0x5e>;
				phandle = <0x5e>;

				pins_cmd_dat {
					output-low;
					pins = <0x2c00>;
					slew-rate = <0x01>;
				};
			};

			cam1@3 {
				linux,phandle = <0x5f>;
				phandle = <0x5f>;

				pins_cmd_dat {
					output-high;
					pins = <0x2c00>;
					slew-rate = <0x01>;
				};
			};

			cam@0 {
				linux,phandle = <0x60>;
				phandle = <0x60>;

				pins_cmd_dat {
					output-low;
					pins = <0x4000>;
					slew-rate = <0x01>;
				};
			};

			cam@1 {
				linux,phandle = <0x61>;
				phandle = <0x61>;

				pins_cmd_dat {
					output-high;
					pins = <0x4000>;
					slew-rate = <0x01>;
				};
			};

			camdefault {
				linux,phandle = <0x57>;
				phandle = <0x57>;
			};

			clockbuf@1 {
				linux,phandle = <0x17>;
				phandle = <0x17>;

				pins_cmd0_dat {
					pins = <0x6e01>;
				};

				pins_cmd1_dat {
					pins = <0x6f01>;
				};

				pins_cmd2_dat {
					pins = <0x7001>;
				};

				pins_cmd3_dat {
					pins = <0x7101>;
				};

				pins_cmd4_dat {
					pins = <0x7201>;
				};
			};

			clockbuf@2 {
				linux,phandle = <0x18>;
				phandle = <0x18>;

				pins_cmd0_dat {
					pins = <0x6e04>;
				};

				pins_cmd1_dat {
					pins = <0x6f04>;
				};

				pins_cmd2_dat {
					pins = <0x7004>;
				};

				pins_cmd3_dat {
					pins = <0x7104>;
				};

				pins_cmd4_dat {
					pins = <0x7204>;
				};
			};

			default {
				linux,phandle = <0x6b>;
				phandle = <0x6b>;
			};

			drvvbus_high {
				linux,phandle = <0x3a>;
				phandle = <0x3a>;

				pins_cmd_dat {
					bias-pull-down = <0x00>;
					output-high;
					pins = <0x5300>;
					slew-rate = <0x01>;
				};
			};

			drvvbus_init {
				linux,phandle = <0x38>;
				phandle = <0x38>;

				pins_cmd_dat {
					bias-pull-down = <0x00>;
					pins = <0x5300>;
					slew-rate = <0x01>;
				};
			};

			drvvbus_low {
				linux,phandle = <0x39>;
				phandle = <0x39>;

				pins_cmd_dat {
					bias-pull-down = <0x00>;
					output-low;
					pins = <0x5300>;
					slew-rate = <0x01>;
				};
			};

			eint0default {
				linux,phandle = <0x70>;
				phandle = <0x70>;
			};

			eint@0 {
				linux,phandle = <0x71>;
				phandle = <0x71>;

				pins_cmd_dat {
					bias-disable;
					pins = <0xa00>;
					slew-rate = <0x00>;
				};
			};

			eint@6 {
				linux,phandle = <0x76>;
				phandle = <0x76>;

				pins_cmd_dat {
					bias-disable;
					pins = <0x600>;
					slew-rate = <0x00>;
				};
			};

			eintoutput0 {
				linux,phandle = <0x72>;
				phandle = <0x72>;

				pins_cmd_dat {
					output-low;
					pins = <0xa00>;
					slew-rate = <0x01>;
				};
			};

			eintoutput1 {
				linux,phandle = <0x73>;
				phandle = <0x73>;

				pins_cmd_dat {
					output-high;
					pins = <0xa00>;
					slew-rate = <0x01>;
				};
			};

			flashlight@0 {
				linux,phandle = <0x62>;
				phandle = <0x62>;

				pins_cmd_dat {
					output-low;
					pins = <0x3700>;
					slew-rate = <0x01>;
				};
			};

			flashlight@1 {
				linux,phandle = <0x63>;
				phandle = <0x63>;

				pins_cmd_dat {
					output-high;
					pins = <0x3700>;
					slew-rate = <0x01>;
				};
			};

			flashlight@2 {
				linux,phandle = <0x64>;
				phandle = <0x64>;

				pins_cmd_dat {
					output-low;
					pins = <0x4e00>;
					slew-rate = <0x01>;
				};
			};

			flashlight@3 {
				linux,phandle = <0x65>;
				phandle = <0x65>;

				pins_cmd_dat {
					output-high;
					pins = <0x4e00>;
					slew-rate = <0x01>;
				};
			};

			flashlight@4 {
				linux,phandle = <0x66>;
				phandle = <0x66>;

				pins_cmd_dat {
					pins = <0x4e05>;
				};
			};

			gpslna@0 {
				linux,phandle = <0x6c>;
				phandle = <0x6c>;

				pins_cmd_dat {
					bias-disable;
					output-low;
					pins = <0x4f00>;
					slew-rate = <0x00>;
				};
			};

			gpslna@1 {
				linux,phandle = <0x6d>;
				phandle = <0x6d>;

				pins_cmd_dat {
					output-high;
					pins = <0x4f00>;
					slew-rate = <0x01>;
				};
			};

			gpslna@2 {
				linux,phandle = <0x6e>;
				phandle = <0x6e>;

				pins_cmd_dat {
					output-low;
					pins = <0x4f00>;
					slew-rate = <0x01>;
				};
			};

			gsensorpincfg {
				linux,phandle = <0x8e>;
				phandle = <0x8e>;

				pins_cmd_dat {
					bias-pull-down = <0x00>;
					pins = <0x400>;
					slew-rate = <0x00>;
				};
			};

			gyrodefaultcfg {
				linux,phandle = <0x91>;
				phandle = <0x91>;
			};

			gyropincfg {
				linux,phandle = <0x92>;
				phandle = <0x92>;

				pins_cmd_dat {
					bias-pull-down = <0x00>;
					pins = <0x4300>;
					slew-rate = <0x00>;
				};
			};

			iddig_irq_init {
				linux,phandle = <0x37>;
				phandle = <0x37>;

				pins_cmd_dat {
					bias-pull-up = <0x00>;
					pins = <0x01>;
					slew-rate = <0x00>;
				};
			};

			irtx_gpio_led_def@gpio19 {
				linux,phandle = <0x1f>;
				phandle = <0x1f>;

				pins_cmd_dat {
					bias-disable;
					input-schmitt-enable = <0x00>;
					output-high;
					pins = <0x1300>;
					slew-rate = <0x01>;
				};
			};

			irtx_gpio_led_set@gpio19 {
				linux,phandle = <0x20>;
				phandle = <0x20>;

				pins_cmd_dat {
					pins = <0x1302>;
				};
			};

			lcm_mode@0 {
				linux,phandle = <0x4b>;
				phandle = <0x4b>;

				pins_cmd_dat {
					pins = <0x5000>;
				};
			};

			lcm_mode@1 {
				linux,phandle = <0x4c>;
				phandle = <0x4c>;

				pins_cmd_dat {
					pins = <0x5001>;
				};
			};

			lcm_mode@2 {
				linux,phandle = <0x4d>;
				phandle = <0x4d>;

				pins_cmd_dat {
					pins = <0x5002>;
				};
			};

			lcm_mode@3 {
				linux,phandle = <0x4e>;
				phandle = <0x4e>;

				pins_cmd_dat {
					pins = <0x5003>;
				};
			};

			lcm_mode@4 {
				linux,phandle = <0x4f>;
				phandle = <0x4f>;

				pins_cmd_dat {
					pins = <0x5004>;
				};
			};

			lcm_mode@5 {
				linux,phandle = <0x50>;
				phandle = <0x50>;

				pins_cmd_dat {
					pins = <0x5005>;
				};
			};

			lcm_mode@6 {
				linux,phandle = <0x51>;
				phandle = <0x51>;

				pins_cmd_dat {
					pins = <0x5006>;
				};
			};

			lcm_mode@7 {
				linux,phandle = <0x52>;
				phandle = <0x52>;

				pins_cmd_dat {
					pins = <0x5007>;
				};
			};

			lcm_mode_default {
				linux,phandle = <0x4a>;
				phandle = <0x4a>;

				pins_cmd_dat {
					pins = <0x5000>;
				};
			};

			mmc0@default {
				linux,phandle = <0x04>;
				phandle = <0x04>;

				pins_clk {
					drive-strength = [02];
				};

				pins_cmd {
					drive-strength = [02];
				};

				pins_dat {
					drive-strength = [02];
				};

				pins_ds {
					drive-strength = [02];
				};

				pins_rst {
					drive-strength = [02];
				};
			};

			mmc0@register_default {
				cmd_edge = [01];
				cmdrddly = [00];
				cmdrrddly = [00];
				dat0rddly = [00];
				dat1rddly = [00];
				dat2rddly = [00];
				dat3rddly = [00];
				dat4rddly = [00];
				dat5rddly = [00];
				dat6rddly = [00];
				dat7rddly = [00];
				datwrddly = [00];
				ett-hs200-cells = <0x0c>;
				ett-hs200-default = <0xb0 0x380 0x00 0xb0 0x7c00 0x00 0xb4 0x38 0x01 0x04 0x02 0x00 0xf0 0x1f0000 0x07 0xf0 0x7c00000 0x0b 0xb4 0x07 0x01 0xf0 0x1f 0x0b 0x04 0x400 0x00 0xf8 0x1f000000 0x07 0xf0 0x1f00 0x09 0x04 0x04 0x00>;
				ett-hs400-cells = <0x08>;
				ett-hs400-default = <0xb0 0x380 0x00 0xb0 0x7c00 0x00 0x188 0x7c 0x02 0x188 0x1f000 0x10 0xb4 0x38 0x01 0x04 0x02 0x00 0xf0 0x1f0000 0x06 0xf0 0x7c00000 0x06>;
				linux,phandle = <0x05>;
				phandle = <0x05>;
				rdata_edge = [01];
				wdata_edge = [01];
			};

			mmc1@ddr50 {
				linux,phandle = <0x09>;
				phandle = <0x09>;

				pins_clk {
					drive-strength = [03];
				};

				pins_cmd {
					drive-strength = [02];
				};

				pins_dat {
					drive-strength = [02];
				};
			};

			mmc1@default {
				linux,phandle = <0x06>;
				phandle = <0x06>;

				pins_clk {
					drive-strength = [03];
				};

				pins_cmd {
					drive-strength = [03];
				};

				pins_dat {
					drive-strength = [03];
				};
			};

			mmc1@register_default {
				cmd_edge = [01];
				cmdrddly = [00];
				cmdrrddly = [00];
				dat0rddly = [00];
				dat1rddly = [00];
				dat2rddly = [00];
				dat3rddly = [00];
				datwrddly = [00];
				linux,phandle = <0x0a>;
				phandle = <0x0a>;
				rdata_edge = [01];
				wdata_edge = [01];
			};

			mmc1@sdr104 {
				linux,phandle = <0x07>;
				phandle = <0x07>;

				pins_clk {
					drive-strength = [03];
				};

				pins_cmd {
					drive-strength = [02];
				};

				pins_dat {
					drive-strength = [02];
				};
			};

			mmc1@sdr50 {
				linux,phandle = <0x08>;
				phandle = <0x08>;

				pins_clk {
					drive-strength = [03];
				};

				pins_cmd {
					drive-strength = [02];
				};

				pins_dat {
					drive-strength = [02];
				};
			};

			pmicclkmode0 {
				linux,phandle = <0x3f>;
				phandle = <0x3f>;

				pins_cmd0_dat {
					pins = <0x8f00>;
				};

				pins_cmd1_dat {
					pins = <0x9000>;
				};

				pins_cmd2_dat {
					pins = <0x9100>;
				};
			};

			pmicclkmode1 {
				linux,phandle = <0x40>;
				phandle = <0x40>;

				pins_cmd0_dat {
					pins = <0x8f01>;
				};

				pins_cmd1_dat {
					pins = <0x9001>;
				};

				pins_cmd2_dat {
					pins = <0x9101>;
				};
			};

			rstoutput0 {
				linux,phandle = <0x74>;
				phandle = <0x74>;

				pins_cmd_dat {
					output-low;
					pins = <0x3e00>;
					slew-rate = <0x01>;
				};
			};

			rstoutput1 {
				linux,phandle = <0x75>;
				phandle = <0x75>;

				pins_cmd_dat {
					output-high;
					pins = <0x3e00>;
					slew-rate = <0x01>;
				};
			};

			ssw0default {
				linux,phandle = <0x77>;
				phandle = <0x77>;
			};

			ssw@1 {
				linux,phandle = <0x78>;
				phandle = <0x78>;

				pins_cmd0_dat {
					pins = <0x805>;
				};

				pins_cmd1_dat {
					pins = <0x904>;
				};
			};

			ssw@2 {
				linux,phandle = <0x79>;
				phandle = <0x79>;

				pins_cmd0_dat {
					pins = <0x802>;
				};

				pins_cmd1_dat {
					pins = <0x904>;
				};
			};

			ssw@3 {
				linux,phandle = <0x7a>;
				phandle = <0x7a>;

				pins_cmd0_dat {
					pins = <0xa301>;
					slew-rate = <0x01>;
				};

				pins_cmd1_dat {
					pins = <0xa401>;
					slew-rate = <0x01>;
				};

				pins_cmd2_dat {
					bias-pull-up = <0x00>;
					pins = <0xa501>;
					slew-rate = <0x00>;
				};

				pins_cmd3_dat {
					pins = <0xa001>;
					slew-rate = <0x01>;
				};

				pins_cmd4_dat {
					pins = <0xa101>;
					slew-rate = <0x01>;
				};

				pins_cmd5_dat {
					bias-pull-up = <0x00>;
					pins = <0xa201>;
					slew-rate = <0x00>;
				};
			};

			ssw@4 {
				linux,phandle = <0x7b>;
				phandle = <0x7b>;

				pins_cmd0_dat {
					pins = <0xa304>;
				};

				pins_cmd1_dat {
					pins = <0xa404>;
				};

				pins_cmd2_dat {
					pins = <0xa504>;
				};

				pins_cmd3_dat {
					pins = <0xa001>;
				};

				pins_cmd4_dat {
					pins = <0xa101>;
				};

				pins_cmd5_dat {
					pins = <0xa201>;
				};
			};

			uart0_rx_clear@gpio74 {
				linux,phandle = <0x23>;
				phandle = <0x23>;

				pins_cmd_dat {
					output-high;
					pins = <0x4a00>;
					slew-rate = <0x01>;
				};
			};

			uart0_rx_set@gpio74 {
				linux,phandle = <0x22>;
				phandle = <0x22>;

				pins_cmd_dat {
					pins = <0x4a01>;
				};
			};

			uart0_tx_clear@gpio75 {
				linux,phandle = <0x25>;
				phandle = <0x25>;

				pins_cmd_dat {
					output-high;
					pins = <0x4b00>;
					slew-rate = <0x01>;
				};
			};

			uart0_tx_set@gpio75 {
				linux,phandle = <0x24>;
				phandle = <0x24>;

				pins_cmd_dat {
					pins = <0x4b01>;
				};
			};

			uart0gpiodefault {
				linux,phandle = <0x21>;
				phandle = <0x21>;
			};

			uart1_rx_clear@gpio76 {
				linux,phandle = <0x28>;
				phandle = <0x28>;

				pins_cmd_dat {
					output-high;
					pins = <0x4c00>;
					slew-rate = <0x01>;
				};
			};

			uart1_rx_set@gpio76 {
				linux,phandle = <0x27>;
				phandle = <0x27>;

				pins_cmd_dat {
					pins = <0x4c01>;
				};
			};

			uart1_tx_clear@gpio77 {
				linux,phandle = <0x2a>;
				phandle = <0x2a>;

				pins_cmd_dat {
					output-high;
					pins = <0x4d00>;
					slew-rate = <0x01>;
				};
			};

			uart1_tx_set@gpio77 {
				linux,phandle = <0x29>;
				phandle = <0x29>;

				pins_cmd_dat {
					pins = <0x4d01>;
				};
			};

			uart1gpiodefault {
				linux,phandle = <0x26>;
				phandle = <0x26>;
			};

			uart2_rx_clear@gpio57 {
				linux,phandle = <0x2d>;
				phandle = <0x2d>;

				pins_cmd_dat {
					output-high;
					pins = <0x3900>;
					slew-rate = <0x01>;
				};
			};

			uart2_rx_set@gpio57 {
				linux,phandle = <0x2c>;
				phandle = <0x2c>;

				pins_cmd_dat {
					pins = <0x3901>;
				};
			};

			uart2_tx_clear@gpio58 {
				linux,phandle = <0x2f>;
				phandle = <0x2f>;

				pins_cmd_dat {
					output-high;
					pins = <0x3a00>;
					slew-rate = <0x01>;
				};
			};

			uart2_tx_set@gpio58 {
				linux,phandle = <0x2e>;
				phandle = <0x2e>;

				pins_cmd_dat {
					pins = <0x3a01>;
				};
			};

			uart2gpiodefault {
				linux,phandle = <0x2b>;
				phandle = <0x2b>;
			};

			uart3_rx_clear@gpio59 {
				linux,phandle = <0x32>;
				phandle = <0x32>;

				pins_cmd_dat {
					output-high;
					pins = <0x3b00>;
					slew-rate = <0x01>;
				};
			};

			uart3_rx_set@gpio59 {
				linux,phandle = <0x31>;
				phandle = <0x31>;

				pins_cmd_dat {
					pins = <0x3b01>;
				};
			};

			uart3_tx_clear@gpio60 {
				linux,phandle = <0x34>;
				phandle = <0x34>;

				pins_cmd_dat {
					output-high;
					pins = <0x3c00>;
					slew-rate = <0x01>;
				};
			};

			uart3_tx_set@gpio60 {
				linux,phandle = <0x33>;
				phandle = <0x33>;

				pins_cmd_dat {
					pins = <0x3c01>;
				};
			};

			uart3gpiodefault {
				linux,phandle = <0x30>;
				phandle = <0x30>;
			};

			usb_default {
				linux,phandle = <0x36>;
				phandle = <0x36>;
			};

			vsram0default {
				linux,phandle = <0x14>;
				phandle = <0x14>;
			};

			vsram@1 {
				linux,phandle = <0x15>;
				phandle = <0x15>;

				pins_cmd_dat {
					output-low;
					pins = <0x8c00>;
					slew-rate = <0x01>;
				};
			};

			vsram@2 {
				linux,phandle = <0x16>;
				phandle = <0x16>;

				pins_cmd_dat {
					output-high;
					pins = <0x8c00>;
					slew-rate = <0x01>;
				};
			};
		};

		ptp_fsm@1100b000 {
			compatible = "mediatek,ptp_fsm_v1";
			interrupts = <0x00 0x7d 0x08>;
			reg = <0x1100b000 0x1000>;
		};

		pwm@11006000 {
			clock-names = "PWM-main\0PWM1-main\0PWM2-main\0PWM3-main\0PWM4-main\0PWM5-main";
			clocks = <0x02 0x0a 0x02 0x03 0x02 0x04 0x02 0x05 0x02 0x06 0x02 0x07>;
			compatible = "mediatek,pwm";
			interrupts = <0x00 0x4d 0x08>;
			reg = <0x11006000 0x1000>;
		};

		pwrap@10001000 {
			compatible = "mediatek,PWRAP";
			interrupts = <0x00 0xa3 0x04>;
			reg = <0x10001000 0x1000>;
		};

		scpsys@10000000 {
			#clock-cells = <0x01>;
			compatible = "mediatek,mt6735-scpsys";
			linux,phandle = <0x13>;
			phandle = <0x13>;
			reg = <0x10000000 0x1000 0x10006000 0x1000>;
		};

		simswitch {
			compatible = "mediatek,sim_switch";
			pinctrl-0 = <0x77>;
			pinctrl-1 = <0x78>;
			pinctrl-2 = <0x79>;
			pinctrl-3 = <0x7a>;
			pinctrl-4 = <0x7b>;
			pinctrl-names = "default\0hot_plug_mode1\0hot_plug_mode2\0two_sims_bound_to_md1\0sim1_md3_sim2_md1";
		};

		sleep@10006000 {
			compatible = "mediatek,sleep";
			interrupts = <0x00 0xa5 0x08 0x00 0xa6 0x08 0x00 0xa7 0x08 0x00 0xa8 0x08>;
			reg = <0x10006000 0x1000>;
		};

		smi_common@14016000 {
			clock-names = "smi-common\0smi-larb0\0img-larb2\0vdec0-vdec\0vdec1-larb\0venc-larb\0venc-venc\0mtcmos-ven\0mtcmos-vde\0mtcmos-isp\0mtcmos-dis";
			clocks = <0x1a 0x01 0x1a 0x02 0x1c 0x01 0x1b 0x01 0x1b 0x02 0x1d 0x01 0x1d 0x02 0x13 0x08 0x13 0x07 0x13 0x06 0x13 0x04>;
			compatible = "mediatek,smi_common";
			reg = <0x14016000 0x1000 0x14015000 0x1000 0x16010000 0x1000 0x15001000 0x1000 0x17001000 0x1000>;
		};

		smi_larb0@14015000 {
			compatible = "mediatek,smi_larb0";
			reg = <0x14015000 0x1000>;
		};

		smi_larb1@16010000 {
			compatible = "mediatek,smi_larb1";
			interrupts = <0x00 0xb1 0x08>;
			reg = <0x16010000 0x1000>;
		};

		smi_larb2@15001000 {
			compatible = "mediatek,smi_larb2";
			interrupts = <0x00 0xb2 0x08>;
			reg = <0x15001000 0x1000>;
		};

		smi_larb3@17001000 {
			compatible = "mediatek,smi_larb3";
			interrupts = <0x00 0xca 0x08>;
			reg = <0x17001000 0x1000>;
		};

		spi@1100a000 {
			cell-index = <0x00>;
			clock-div = <0x01>;
			clock-frequency = <0x67f3540>;
			clock-names = "spi-main";
			clocks = <0x02 0x1d>;
			compatible = "mediatek,mt6735-spi";
			interrupts = <0x00 0x76 0x08>;
			reg = <0x1100a000 0x1000>;
			spi-padmacro = <0x00>;
		};

		sys_cirq@10204000 {
			compatible = "mediatek,mt6735-sys_cirq";
			interrupts = <0x00 0xe7 0x08>;
			mediatek,cirq_num = <0x9f>;
			mediatek,spi_start_offset = <0x48>;
			reg = <0x10204000 0x1000>;
		};

		syscfg_pctl_a@10211000 {
			compatible = "mediatek,mt6735-pctl-a-syscfg\0syscon";
			linux,phandle = <0x1e>;
			phandle = <0x1e>;
			reg = <0x00 0x9bceb8 0x00 0x3e8>;
		};

		therm_ctrl@1100b000 {
			clock-names = "therm-main";
			clocks = <0x02 0x02>;
			compatible = "mediatek,mt6735-therm_ctrl";
			interrupts = <0x00 0x4e 0x08>;
			reg = <0x1100b000 0x1000>;
		};

		timer {
			clock-frequency = <0xc65d40>;
			compatible = "arm,armv8-timer";
			interrupts = <0x01 0x0d 0x08 0x01 0x0e 0x08 0x01 0x0b 0x08 0x01 0x0a 0x08>;
		};

		topckgen@10210000 {
			#clock-cells = <0x01>;
			compatible = "mediatek,mt6735-topckgen";
			linux,phandle = <0x03>;
			phandle = <0x03>;
			reg = <0x10210000 0x1000>;
		};

		toprgu@10212000 {
			compatible = "mediatek,mt6735-rgu";
			interrupts = <0x00 0x80 0x02>;
			reg = <0x10212000 0x1000>;
		};

		touch {
			compatible = "mediatek,mt6735-touch";
			debounce = <0x0a 0x00>;
			interrupt-parent = <0x0c>;
			interrupts = <0x0a 0x08>;
			pinctrl-0 = <0x70>;
			pinctrl-1 = <0x71>;
			pinctrl-2 = <0x72>;
			pinctrl-3 = <0x73>;
			pinctrl-4 = <0x74>;
			pinctrl-5 = <0x75>;
			pinctrl-names = "default\0state_eint_as_int\0state_eint_output0\0state_eint_output1\0state_rst_output0\0state_rst_output1";
			status = "okay";
			tpd-filter-custom-prameters = <0x00 0x00 0x00 0x00 0x00 0x00 0x00 0x00 0x00 0x00 0x00 0x00>;
			tpd-filter-custom-speed = <0x00 0x00 0x00>;
			tpd-filter-enable = <0x01>;
			tpd-filter-pixel-density = <0xba>;
			tpd-key-dim-local = <0x5a 0x373 0x64 0x28 0xe6 0x373 0x64 0x28 0x172 0x373 0x64 0x28 0x00 0x00 0x00 0x00>;
			tpd-key-local = <0x8b 0xac 0x9e 0x00>;
			tpd-key-num = <0x03>;
			tpd-max-touch-num = <0x05>;
			tpd-resolution = <0x438 0x780>;
			use-tpd-button = <0x00>;
			vtouch-supply = <0x6f>;
		};

		usb20@11200000 {
			cell-index = <0x00>;
			clock-names = "usb0";
			clocks = <0x02 0x0b>;
			compatible = "mediatek,mt6735-usb20";
			drvvbus_gpio = <0x53 0x02>;
			iddig_gpio = <0x00 0x01>;
			interrupts = <0x00 0x48 0x08>;
			mode = <0x02>;
			multipoint = <0x01>;
			num_eps = <0x10>;
			pinctrl-0 = <0x36>;
			pinctrl-1 = <0x37>;
			pinctrl-2 = <0x38>;
			pinctrl-3 = <0x39>;
			pinctrl-4 = <0x3a>;
			pinctrl-names = "usb_default\0iddig_irq_init\0drvvbus_init\0drvvbus_low\0drvvbus_high";
			reg = <0x11200000 0x10000 0x11210000 0x10000>;
			status = "okay";
			vusb33-supply = <0x35>;
		};

		vdec@16020000 {
			compatible = "mediatek,mt6735-vdec";
			interrupts = <0x00 0xb3 0x08>;
			reg = <0x16020000 0x10000>;
		};

		vdec_gcon@16000000 {
			clock-names = "MT_CG_DISP0_SMI_COMMON\0MT_CG_VDEC0_VDEC\0MT_CG_VDEC1_LARB\0MT_CG_VENC_VENC\0MT_CG_VENC_LARB\0MT_CG_TOP_MUX_VDEC\0MT_CG_TOP_SYSPLL1_D2\0MT_CG_TOP_SYSPLL1_D4\0MT_SCP_SYS_VDE\0MT_SCP_SYS_VEN\0MT_SCP_SYS_DIS";
			clocks = <0x1a 0x01 0x1b 0x01 0x1b 0x02 0x1d 0x02 0x1d 0x01 0x03 0x06 0x03 0x32 0x03 0x33 0x13 0x07 0x13 0x08 0x13 0x04>;
			compatible = "mediatek,mt6735-vdec_gcon";
			interrupts = <0x00 0xb3 0x08>;
			reg = <0x16000000 0x1000>;
		};

		vdecsys@16000000 {
			#clock-cells = <0x01>;
			compatible = "mediatek,mt6735-vdecsys";
			interrupts = <0x00 0xb3 0x08>;
			linux,phandle = <0x1b>;
			phandle = <0x1b>;
			reg = <0x16000000 0x1000>;
		};

		venc@17002000 {
			compatible = "mediatek,mt6735-venc";
			interrupts = <0x00 0xb4 0x08>;
			reg = <0x17002000 0x1000>;
		};

		venc_gcon@17000000 {
			compatible = "mediatek,mt6735-venc_gcon";
			interrupts = <0x00 0xb4 0x08>;
			reg = <0x17000000 0x1000>;
		};

		vencsys@17000000 {
			#clock-cells = <0x01>;
			compatible = "mediatek,mt6735-vencsys";
			interrupts = <0x00 0xb4 0x08>;
			linux,phandle = <0x1d>;
			phandle = <0x1d>;
			reg = <0x17000000 0x1000>;
		};

		wifi@180F0000 {
			clock-names = "wifi-dma";
			clocks = <0x02 0x0d>;
			compatible = "mediatek,wifi";
			interrupts = <0x00 0xe2 0x08>;
			reg = <0x180f0000 0x5c>;
		};
	};

	trusty {
		#address-cells = <0x02>;
		#size-cells = <0x02>;
		compatible = "android,trusty-smc-v1";
		ranges;

		irq {
			compatible = "android,trusty-irq-v1";
			ppi-interrupt-parent = <0x01>;
		};

		log {
			compatible = "android,trusty-log-v1";
		};

		mtee {
			compatible = "mediatek,trusty-mtee-v1";
		};

		virtio {
			compatible = "android,trusty-virtio-v1";
		};
	};

	utos {
		compatible = "microtrust,utos";
		interrupts = <0x00 0xf4 0x01 0x00 0xf5 0x01 0x00 0xf6 0x01 0x00 0xfa 0x01 0x00 0xfb 0x01 0x00 0xfc 0x01 0x00 0xfd 0x01 0x00 0xff 0x01>;
	};

	vcorefs {
		clock-names = "mux_axi\0syspll_d5\0syspll1_d4";
		clocks = <0x03 0x01 0x03 0x30 0x03 0x33>;
		compatible = "mediatek,mt6735-vcorefs";
	};

	vibrator@0 {
		compatible = "mediatek,vibrator";
		vib_limit = <0x09>;
		vib_timer = <0x19>;
		vib_vol = <0x05>;
	};
};
